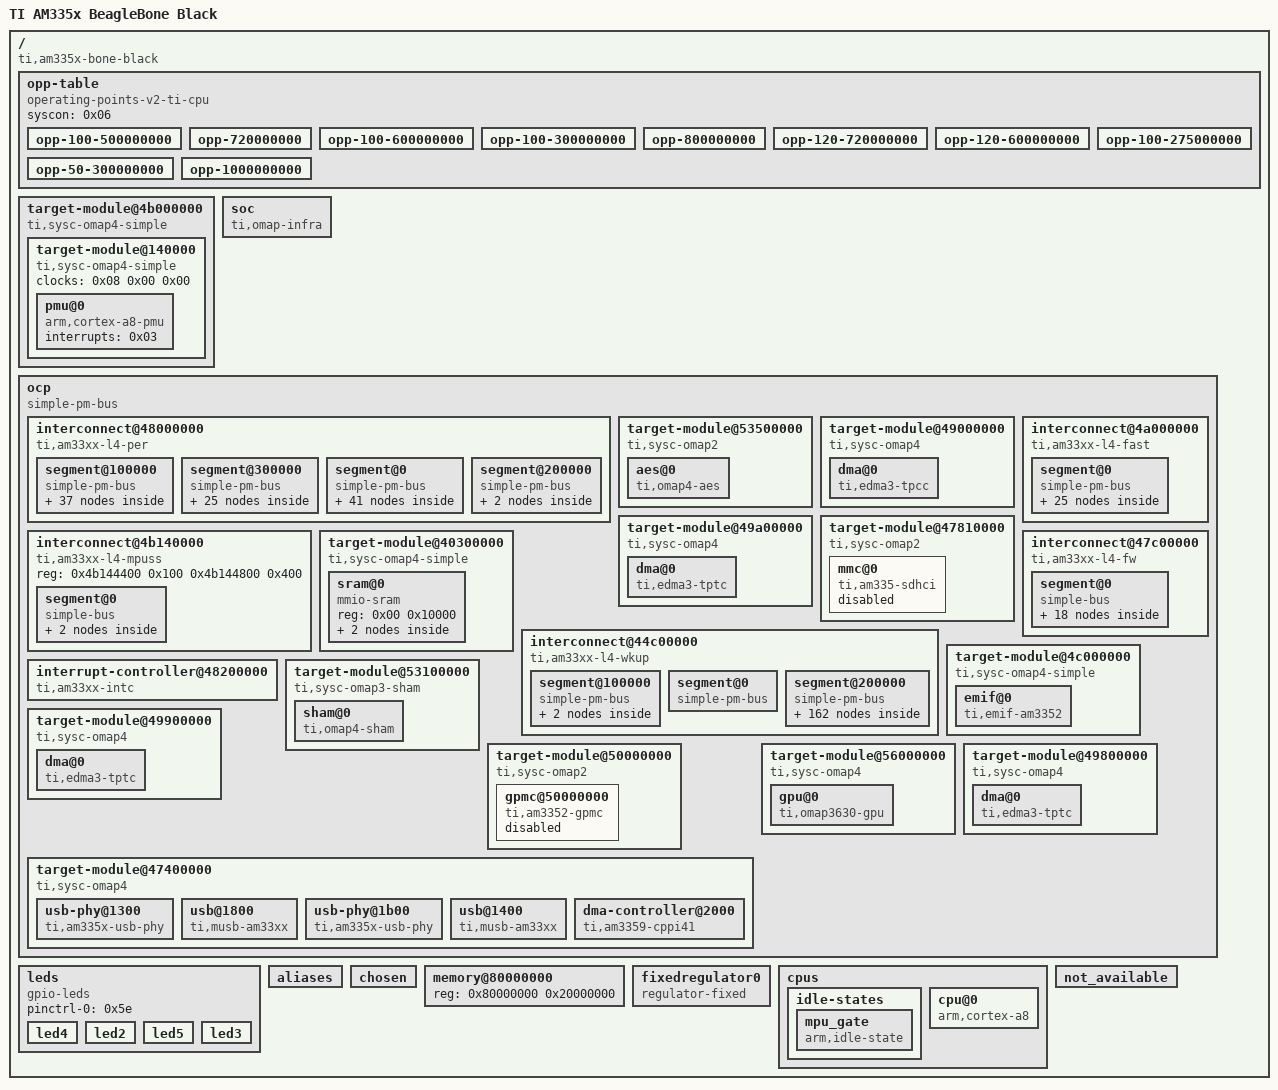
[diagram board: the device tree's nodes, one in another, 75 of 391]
/dts-v1/;

/ {
	compatible = "ti,am335x-bone-black\0ti,am335x-bone\0ti,am33xx";
	serial-number = "4016BBBK0E84";
	model = "TI AM335x BeagleBone Black";
	interrupt-parent = <0x01>;
	#address-cells = <0x01>;
	#size-cells = <0x01>;

	opp-table {
		compatible = "operating-points-v2-ti-cpu";
		phandle = <0x02>;
		syscon = <0x06>;

		opp-100-500000000 {
			opp-microvolt = <0x10c8e0 0x1072f0 0x111ed0>;
			opp-hz = <0x00 0x1dcd6500>;
			opp-supported-hw = <0x01 0xffff>;
		};

		opp-720000000 {
			opp-microvolt = <0x1339e0 0x12d770 0x139c50>;
			opp-hz = <0x00 0x2aea5400>;
			opp-supported-hw = <0x01 0xffff>;
		};

		opp-100-600000000 {
			opp-microvolt = <0x10c8e0 0x1072f0 0x111ed0>;
			opp-hz = <0x00 0x23c34600>;
			opp-supported-hw = <0x06 0x40>;
		};

		opp-100-300000000 {
			opp-microvolt = <0x10c8e0 0x1072f0 0x111ed0>;
			opp-hz = <0x00 0x11e1a300>;
			opp-suspend;
			opp-supported-hw = <0x06 0x20>;
		};

		opp-800000000 {
			opp-microvolt = <0x1339e0 0x12d770 0x139c50>;
			opp-hz = <0x00 0x2faf0800>;
			opp-supported-hw = <0x06 0x100>;
		};

		opp-120-720000000 {
			opp-microvolt = <0x124f80 0x11f1c0 0x12ad40>;
			opp-hz = <0x00 0x2aea5400>;
			opp-supported-hw = <0x06 0x80>;
		};

		opp-120-600000000 {
			opp-microvolt = <0x124f80 0x11f1c0 0x12ad40>;
			opp-hz = <0x00 0x23c34600>;
			opp-supported-hw = <0x01 0xffff>;
		};

		opp-100-275000000 {
			opp-microvolt = <0x10c8e0 0x1072f0 0x111ed0>;
			opp-hz = <0x00 0x10642ac0>;
			opp-suspend;
			opp-supported-hw = <0x01 0xff>;
		};

		opp-50-300000000 {
			opp-microvolt = <0xe7ef0 0xe34b8 0xec928>;
			opp-hz = <0x00 0x11e1a300>;
			opp-suspend;
			opp-supported-hw = <0x06 0x10>;
		};

		opp-1000000000 {
			opp-microvolt = <0x1437c8 0x13d044 0x149f4c>;
			opp-hz = <0x00 0x3b9aca00>;
			opp-supported-hw = <0x06 0x100>;
		};
	};

	target-module@4b000000 {
		compatible = "ti,sysc-omap4-simple\0ti,sysc";
		clocks = <0x07 0xb8 0x00>;
		clock-names = "fck";
		ti,no-idle;
		ranges = <0x00 0x4b000000 0x1000000>;
		#address-cells = <0x01>;
		#size-cells = <0x01>;

		target-module@140000 {
			compatible = "ti,sysc-omap4-simple\0ti,sysc";
			clocks = <0x08 0x00 0x00>;
			clock-names = "fck";
			ranges = <0x00 0x140000 0xec0000>;
			#address-cells = <0x01>;
			#size-cells = <0x01>;

			pmu@0 {
				compatible = "arm,cortex-a8-pmu";
				interrupts = <0x03>;
			};
		};
	};

	__symbols__ {
		dpll_per_m2_div4_wkupdm_ck = "/ocp/interconnect@44c00000/segment@200000/target-module@0/prcm@0/clocks/clock-dpll-per-m2-div4-wkupdm";
		cpsw_port1 = "/ocp/interconnect@4a000000/segment@0/target-module@100000/switch@0/ethernet-ports/port@1";
		sha0_fck = "/ocp/interconnect@44c00000/segment@200000/target-module@10000/scm@0/scm_conf@0/clocks/clock-sha0-fck";
		prm_mpu = "/ocp/interconnect@44c00000/segment@200000/target-module@0/prcm@0/prm@e00";
		dpll_core_m4_div2_ck = "/ocp/interconnect@44c00000/segment@200000/target-module@0/prcm@0/clocks/clock-dpll-core-m4-div2";
		cpsw_sleep = "/ocp/interconnect@44c00000/segment@200000/target-module@10000/scm@0/pinmux@800/cpsw-sleep-pins";
		ehrpwm2 = "/ocp/interconnect@48000000/segment@300000/target-module@4000/epwmss@0/pwm@200";
		gpio2 = "/ocp/interconnect@48000000/segment@100000/target-module@ac000/gpio@0";
		prm_gfx = "/ocp/interconnect@44c00000/segment@200000/target-module@0/prcm@0/prm@1100";
		intc = "/ocp/interrupt-controller@48200000";
		ecap2 = "/ocp/interconnect@48000000/segment@300000/target-module@4000/epwmss@0/pwm@100";
		dpll_ddr_m2_ck = "/ocp/interconnect@44c00000/segment@200000/target-module@0/prcm@0/clocks/clock-dpll-ddr-m2@4a0";
		tclkin_ck = "/ocp/interconnect@44c00000/segment@200000/target-module@0/prcm@0/clocks/clock-tclkin";
		edma_tptc0 = "/ocp/target-module@49800000/dma@0";
		l4_rtc_clkctrl = "/ocp/interconnect@44c00000/segment@200000/target-module@0/prcm@0/clock@800/clock@0";
		cape_eeprom3 = "/ocp/interconnect@48000000/segment@100000/target-module@9c000/i2c@0/eeprom@57";
		timer6 = "/ocp/interconnect@48000000/segment@0/target-module@48000/timer@0";
		l4_fast = "/ocp/interconnect@4a000000";
		bone_uart_4 = "/ocp/interconnect@48000000/segment@100000/target-module@a8000/serial@0";
		epwmss2 = "/ocp/interconnect@48000000/segment@300000/target-module@4000/epwmss@0";
		l3s_clkctrl = "/ocp/interconnect@44c00000/segment@200000/target-module@0/prcm@0/clock@0/clock@1c";
		dcan0_fck = "/ocp/interconnect@44c00000/segment@200000/target-module@10000/scm@0/scm_conf@0/clocks/clock-dcan0-fck";
		tps = "/ocp/interconnect@44c00000/segment@200000/target-module@b000/i2c@0/pmic@24";
		gfx_l3_clkctrl = "/ocp/interconnect@44c00000/segment@200000/target-module@0/prcm@0/clock@900/clock@0";
		mcasp0_fck = "/ocp/interconnect@44c00000/segment@200000/target-module@10000/scm@0/scm_conf@0/clocks/clock-mcasp0-fck";
		i2c1 = "/ocp/interconnect@48000000/segment@0/target-module@2a000/i2c@0";
		ldo3_reg = "/ocp/interconnect@44c00000/segment@200000/target-module@b000/i2c@0/pmic@24/regulators/regulator@5";
		dpll_core_m5_ck = "/ocp/interconnect@44c00000/segment@200000/target-module@0/prcm@0/clocks/clock-dpll-core-m5@484";
		mmc3 = "/ocp/target-module@47810000/mmc@0";
		l4_wkup = "/ocp/interconnect@44c00000";
		l4_fw = "/ocp/interconnect@47c00000";
		ehrpwm0 = "/ocp/interconnect@48000000/segment@300000/target-module@0/epwmss@0/pwm@200";
		aes_target = "/ocp/target-module@53500000";
		pru1 = "/ocp/interconnect@4a000000/segment@0/target-module@300000/pruss@0/pru@38000";
		gpio0 = "/ocp/interconnect@44c00000/segment@200000/target-module@7000/gpio@0";
		cpsw_default = "/ocp/interconnect@44c00000/segment@200000/target-module@10000/scm@0/pinmux@800/cpsw-default-pins";
		ecap0 = "/ocp/interconnect@48000000/segment@300000/target-module@0/epwmss@0/pwm@100";
		gpio0_target = "/ocp/interconnect@44c00000/segment@200000/target-module@7000";
		cape_eeprom1 = "/ocp/interconnect@48000000/segment@100000/target-module@9c000/i2c@0/eeprom@55";
		timer4 = "/ocp/interconnect@48000000/segment@0/target-module@44000/timer@0";
		spi0 = "/ocp/interconnect@48000000/segment@0/target-module@30000/spi@0";
		prm_device = "/ocp/interconnect@44c00000/segment@200000/target-module@0/prcm@0/prm@f00";
		davinci_mdio_sleep = "/ocp/interconnect@44c00000/segment@200000/target-module@10000/scm@0/pinmux@800/davinci-mdio-sleep-pins";
		gfx_fclk_clksel_ck = "/ocp/interconnect@44c00000/segment@200000/target-module@0/prcm@0/clocks/clock@52c/clock-gfx-fclk-clksel@1";
		prm_cefuse = "/ocp/interconnect@44c00000/segment@200000/target-module@0/prcm@0/prm@1200";
		dpll_ddr_m2_div2_ck = "/ocp/interconnect@44c00000/segment@200000/target-module@0/prcm@0/clocks/clock-dpll-ddr-m2-div2";
		pruss = "/ocp/interconnect@4a000000/segment@0/target-module@300000/pruss@0";
		epwmss0 = "/ocp/interconnect@48000000/segment@300000/target-module@0/epwmss@0";
		dpll_disp_ck = "/ocp/interconnect@44c00000/segment@200000/target-module@0/prcm@0/clocks/clock@498";
		wkup_m3_ipc = "/ocp/interconnect@44c00000/segment@200000/target-module@10000/scm@0/wkup_m3_ipc@1324";
		l4ls_clkctrl = "/ocp/interconnect@44c00000/segment@200000/target-module@0/prcm@0/clock@0/clock@38";
		timer1_fck = "/ocp/interconnect@44c00000/segment@200000/target-module@0/prcm@0/clocks/clock-timer1-fck@528";
		mmc1 = "/ocp/interconnect@48000000/segment@0/target-module@60000/mmc@0";
		scm = "/ocp/interconnect@44c00000/segment@200000/target-module@10000/scm@0";
		usb1 = "/ocp/target-module@47400000/usb@1800";
		sham_target = "/ocp/target-module@53100000";
		sysclkout_pre_ck = "/ocp/interconnect@44c00000/segment@200000/target-module@0/prcm@0/clocks/clock@700/clock-sysclkout-pre@0";
		cpsw_emac1 = "/ocp/interconnect@4a000000/segment@0/target-module@100000/ethernet@0/slave@300";
		lcd_gclk = "/ocp/interconnect@44c00000/segment@200000/target-module@0/prcm@0/clocks/clock-lcd-gclk@534";
		am33xx_pinmux = "/ocp/interconnect@44c00000/segment@200000/target-module@10000/scm@0/pinmux@800";
		clk_24mhz_clkctrl = "/ocp/interconnect@44c00000/segment@200000/target-module@0/prcm@0/clock@0/clock@14c";
		bone_adc = "/ocp/interconnect@44c00000/segment@200000/target-module@d000/tscadc@0";
		timer5_fck = "/ocp/interconnect@44c00000/segment@200000/target-module@0/prcm@0/clocks/clock-timer5-fck@518";
		user_leds_s0 = "/ocp/interconnect@44c00000/segment@200000/target-module@10000/scm@0/pinmux@800/user-leds-s0-pins";
		l4ls_gclk = "/ocp/interconnect@44c00000/segment@200000/target-module@0/prcm@0/clocks/clock-l4ls-gclk";
		timer2 = "/ocp/interconnect@48000000/segment@0/target-module@40000/timer@0";
		mmc1_pins = "/ocp/interconnect@44c00000/segment@200000/target-module@10000/scm@0/pinmux@800/mmc1-pins";
		mac_sw = "/ocp/interconnect@4a000000/segment@0/target-module@100000/switch@0";
		mbox_wkupm3 = "/ocp/interconnect@48000000/segment@0/target-module@c8000/mailbox@0/mbox-wkup-m3";
		dpll_disp_m2_ck = "/ocp/interconnect@44c00000/segment@200000/target-module@0/prcm@0/clocks/clock-dpll-disp-m2@4a4";
		pm_sram_code = "/ocp/target-module@40300000/sram@0/pm-code-sram@0";
		edma = "/ocp/target-module@49000000/dma@0";
		virt_25000000_ck = "/ocp/interconnect@44c00000/segment@200000/target-module@0/prcm@0/clocks/clock-virt-25000000";
		lcdc_clkctrl = "/ocp/interconnect@44c00000/segment@200000/target-module@0/prcm@0/clock@0/clock@18";
		l4_rtc_cm = "/ocp/interconnect@44c00000/segment@200000/target-module@0/prcm@0/clock@800";
		adc_tsc_fck = "/ocp/interconnect@44c00000/segment@200000/target-module@10000/scm@0/scm_conf@0/clocks/clock-adc-tsc-fck";
		mpu_gate = "/cpus/idle-states/mpu_gate";
		uart4 = "/ocp/interconnect@48000000/segment@100000/target-module@a8000/serial@0";
		ehrpwm1_tbclk = "/ocp/interconnect@44c00000/segment@200000/target-module@10000/scm@0/scm_conf@0/clocks/clock@664/clock-ehrpwm1-tbclk@1";
		cppi41dma = "/ocp/target-module@47400000/dma-controller@2000";
		dpll_per_ck = "/ocp/interconnect@44c00000/segment@200000/target-module@0/prcm@0/clocks/clock@48c";
		dpll_per_m2_div4_ck = "/ocp/interconnect@44c00000/segment@200000/target-module@0/prcm@0/clocks/clock-dpll-per-m2-div4";
		dcdc1_reg = "/ocp/interconnect@44c00000/segment@200000/target-module@b000/i2c@0/pmic@24/regulators/regulator@0";
		mcasp0 = "/ocp/interconnect@48000000/segment@0/target-module@38000/mcasp@0";
		dcan1_fck = "/ocp/interconnect@44c00000/segment@200000/target-module@10000/scm@0/scm_conf@0/clocks/clock-dcan1-fck";
		eqep1 = "/ocp/interconnect@48000000/segment@300000/target-module@2000/epwmss@0/counter@180";
		i2c2_pins = "/ocp/interconnect@44c00000/segment@200000/target-module@10000/scm@0/pinmux@800/i2c2-pins";
		mcasp1_fck = "/ocp/interconnect@44c00000/segment@200000/target-module@10000/scm@0/scm_conf@0/clocks/clock-mcasp1-fck";
		ldo4_reg = "/ocp/interconnect@44c00000/segment@200000/target-module@b000/i2c@0/pmic@24/regulators/regulator@6";
		lcdc = "/ocp/interconnect@48000000/segment@300000/target-module@e000/lcdc@0";
		cpu = "/cpus/cpu@0";
		emmc_pins = "/ocp/interconnect@44c00000/segment@200000/target-module@10000/scm@0/pinmux@800/emmc-pins";
		edma_xbar = "/ocp/interconnect@44c00000/segment@200000/target-module@10000/scm@0/dma-router@f90";
		ocmcram = "/ocp/target-module@40300000/sram@0";
		pm_sram_data = "/ocp/target-module@40300000/sram@0/pm-data-sram@1000";
		l4_mpuss = "/ocp/interconnect@4b140000";
		ocp = "/ocp";
		am335x_adc = "/ocp/interconnect@44c00000/segment@200000/target-module@d000/tscadc@0/adc";
		pruss_tm = "/ocp/interconnect@4a000000/segment@0/target-module@300000";
		mpu_clkctrl = "/ocp/interconnect@44c00000/segment@200000/target-module@0/prcm@0/clock@600/clock@0";
		l3_aon_clkctrl = "/ocp/interconnect@44c00000/segment@200000/target-module@0/prcm@0/clock@400/clock@14";
		uart2 = "/ocp/interconnect@48000000/segment@0/target-module@24000/serial@0";
		prm_per = "/ocp/interconnect@44c00000/segment@200000/target-module@0/prcm@0/prm@c00";
		elm = "/ocp/interconnect@48000000/segment@0/target-module@80000/elm@0";
		scm_clocks = "/ocp/interconnect@44c00000/segment@200000/target-module@10000/scm@0/scm_conf@0/clocks";
		dpll_mpu_ck = "/ocp/interconnect@44c00000/segment@200000/target-module@0/prcm@0/clocks/clock@488";
		l4_per = "/ocp/interconnect@48000000";
		dpll_core_m4_ck = "/ocp/interconnect@44c00000/segment@200000/target-module@0/prcm@0/clocks/clock-dpll-core-m4@480";
		cape3_data = "/ocp/interconnect@48000000/segment@100000/target-module@9c000/i2c@0/eeprom@57/nvmem-layout/cape_data@0";
		cpsw_port2 = "/ocp/interconnect@4a000000/segment@0/target-module@100000/switch@0/ethernet-ports/port@2";
		l3_clkctrl = "/ocp/interconnect@44c00000/segment@200000/target-module@0/prcm@0/clock@0/clock@24";
		timer2_fck = "/ocp/interconnect@44c00000/segment@200000/target-module@0/prcm@0/clocks/clock-timer2-fck@508";
		wkup_cm = "/ocp/interconnect@44c00000/segment@200000/target-module@0/prcm@0/clock@400";
		davinci_mdio_default = "/ocp/interconnect@44c00000/segment@200000/target-module@10000/scm@0/pinmux@800/davinci-mdio-default-pins";
		bone_pinmux = "/ocp/interconnect@44c00000/segment@200000/target-module@10000/scm@0/pinmux@800";
		prcm_clockdomains = "/ocp/interconnect@44c00000/segment@200000/target-module@0/prcm@0/clockdomains";
		gpio3 = "/ocp/interconnect@48000000/segment@100000/target-module@ae000/gpio@0";
		sysclk_div_ck = "/ocp/interconnect@44c00000/segment@200000/target-module@0/prcm@0/clocks/clock-sysclk-div";
		l3s_gclk = "/ocp/interconnect@44c00000/segment@200000/target-module@0/prcm@0/clocks/clock-l3s-gclk";
		rng = "/ocp/interconnect@48000000/segment@300000/target-module@10000/rng@0";
		timer6_fck = "/ocp/interconnect@44c00000/segment@200000/target-module@0/prcm@0/clocks/clock-timer6-fck@51c";
		dpll_mpu_m2_ck = "/ocp/interconnect@44c00000/segment@200000/target-module@0/prcm@0/clocks/clock-dpll-mpu-m2@4a8";
		dcan0 = "/ocp/interconnect@48000000/segment@100000/target-module@cc000/can@0";
		scm_clockdomains = "/ocp/interconnect@44c00000/segment@200000/target-module@10000/scm@0/clockdomains";
		uart0 = "/ocp/interconnect@44c00000/segment@200000/target-module@9000/serial@0";
		edma_tptc1 = "/ocp/target-module@49900000/dma@0";
		smartreflex0_fck = "/ocp/interconnect@44c00000/segment@200000/target-module@10000/scm@0/scm_conf@0/clocks/clock-smartreflex0-fck";
		timer7 = "/ocp/interconnect@48000000/segment@0/target-module@4a000/timer@0";
		davinci_mdio_sw = "/ocp/interconnect@4a000000/segment@0/target-module@100000/switch@0/mdio@1000";
		prcm = "/ocp/interconnect@44c00000/segment@200000/target-module@0/prcm@0";
		usbotg_fck = "/ocp/interconnect@44c00000/segment@200000/target-module@0/prcm@0/clocks/clock-usbotg-fck-8@47c";
		pruss_mem = "/ocp/interconnect@4a000000/segment@0/target-module@300000/pruss@0/memories@0";
		gfx_fck_div_ck = "/ocp/interconnect@44c00000/segment@200000/target-module@0/prcm@0/clocks/clock@52c/clock-gfx-fck-div@0";
		cpsw_125mhz_clkctrl = "/ocp/interconnect@44c00000/segment@200000/target-module@0/prcm@0/clock@0/clock@0";
		l4_cefuse_cm = "/ocp/interconnect@44c00000/segment@200000/target-module@0/prcm@0/clock@a00";
		baseboard_data = "/ocp/interconnect@44c00000/segment@200000/target-module@b000/i2c@0/eeprom@50/nvmem-layout/baseboard_data@0";
		l4fw_gclk = "/ocp/interconnect@44c00000/segment@200000/target-module@0/prcm@0/clocks/clock-l4fw-gclk";
		l3_gclk = "/ocp/interconnect@44c00000/segment@200000/target-module@0/prcm@0/clocks/clock-l3-gclk";
		i2c2 = "/ocp/interconnect@48000000/segment@100000/target-module@9c000/i2c@0";
		davinci_mdio = "/ocp/interconnect@4a000000/segment@0/target-module@100000/ethernet@0/mdio@1000";
		clk_24mhz = "/ocp/interconnect@44c00000/segment@200000/target-module@0/prcm@0/clocks/clock-clk-24mhz";
		ehrpwm1 = "/ocp/interconnect@48000000/segment@300000/target-module@2000/epwmss@0/pwm@200";
		wdt1_fck = "/ocp/interconnect@44c00000/segment@200000/target-module@0/prcm@0/clocks/clock-wdt1-fck@538";
		gpio1 = "/ocp/interconnect@48000000/segment@0/target-module@4c000/gpio@0";
		dpll_per_m2_ck = "/ocp/interconnect@44c00000/segment@200000/target-module@0/prcm@0/clocks/clock-dpll-per-m2@4ac";
		ldo1_reg = "/ocp/interconnect@44c00000/segment@200000/target-module@b000/i2c@0/pmic@24/regulators/regulator@3";
		dcdc2_reg = "/ocp/interconnect@44c00000/segment@200000/target-module@b000/i2c@0/pmic@24/regulators/regulator@1";
		ecap1 = "/ocp/interconnect@48000000/segment@300000/target-module@2000/epwmss@0/pwm@100";
		cape2_data = "/ocp/interconnect@48000000/segment@100000/target-module@9c000/i2c@0/eeprom@56/nvmem-layout/cape_data@0";
		virt_26000000_ck = "/ocp/interconnect@44c00000/segment@200000/target-module@0/prcm@0/clocks/clock-virt-26000000";
		cape_eeprom2 = "/ocp/interconnect@48000000/segment@100000/target-module@9c000/i2c@0/eeprom@56";
		timer5 = "/ocp/interconnect@48000000/segment@0/target-module@46000/timer@0";
		spi1 = "/ocp/interconnect@48000000/segment@100000/target-module@a0000/spi@0";
		usb = "/ocp/target-module@47400000";
		epwmss1 = "/ocp/interconnect@48000000/segment@300000/target-module@2000/epwmss@0";
		pruss_ocp_clkctrl = "/ocp/interconnect@44c00000/segment@200000/target-module@0/prcm@0/clock@0/clock@e8";
		pruss_iepclk_mux = "/ocp/interconnect@4a000000/segment@0/target-module@300000/pruss@0/cfg@26000/clocks/iepclk-mux@30";
		pruss_mii_rt = "/ocp/interconnect@4a000000/segment@0/target-module@300000/pruss@0/mii-rt@32000";
		prm_rtc = "/ocp/interconnect@44c00000/segment@200000/target-module@0/prcm@0/prm@1000";
		sys_clkin_ck = "/ocp/interconnect@44c00000/segment@200000/target-module@10000/scm@0/scm_conf@0/clocks/clock-sys-clkin-22@40";
		i2c0 = "/ocp/interconnect@44c00000/segment@200000/target-module@b000/i2c@0";
		timer2_target = "/ocp/interconnect@48000000/segment@0/target-module@40000";
		mmc2 = "/ocp/interconnect@48000000/segment@100000/target-module@d8000/mmc@0";
		i2c0_pins = "/ocp/interconnect@44c00000/segment@200000/target-module@10000/scm@0/pinmux@800/i2c0-pins";
		ehrpwm2_tbclk = "/ocp/interconnect@44c00000/segment@200000/target-module@10000/scm@0/scm_conf@0/clocks/clock@664/clock-ehrpwm2-tbclk@2";
		bborg_comms_rs485_pins = "/ocp/interconnect@44c00000/segment@200000/target-module@10000/scm@0/pinmux@800/pinmux_comms_rs485_pins";
		gpmc = "/ocp/target-module@50000000/gpmc@50000000";
		aes0_fck = "/ocp/interconnect@44c00000/segment@200000/target-module@10000/scm@0/scm_conf@0/clocks/clock-aes0-fck";
		pru0 = "/ocp/interconnect@4a000000/segment@0/target-module@300000/pruss@0/pru@34000";
		dpll_core_ck = "/ocp/interconnect@44c00000/segment@200000/target-module@0/prcm@0/clocks/clock@490";
		dpll_ddr_ck = "/ocp/interconnect@44c00000/segment@200000/target-module@0/prcm@0/clocks/clock@494";
		wdt2 = "/ocp/interconnect@44c00000/segment@200000/target-module@35000/wdt@0";
		cpu0_opp_table = "/opp-table";
		gpio3_target = "/ocp/interconnect@48000000/segment@100000/target-module@ae000";
		cpsw_125mhz_gclk = "/ocp/interconnect@44c00000/segment@200000/target-module@0/prcm@0/clocks/clock-cpsw-125mhz-gclk";
		pruss_ocp_gclk = "/ocp/interconnect@44c00000/segment@200000/target-module@0/prcm@0/clocks/clock-pruss-ocp-gclk@530";
		cape_eeprom0 = "/ocp/interconnect@48000000/segment@100000/target-module@9c000/i2c@0/eeprom@54";
		timer3 = "/ocp/interconnect@48000000/segment@0/target-module@42000/timer@0";
		usb0_phy = "/ocp/target-module@47400000/usb-phy@1300";
		rng_fck = "/ocp/interconnect@44c00000/segment@200000/target-module@10000/scm@0/scm_conf@0/clocks/clock-rng-fck";
		uart0_pins = "/ocp/interconnect@44c00000/segment@200000/target-module@10000/scm@0/pinmux@800/uart0-pins";
		usb_ctrl_mod = "/ocp/interconnect@44c00000/segment@200000/target-module@10000/scm@0/control@620";
		prm_wkup = "/ocp/interconnect@44c00000/segment@200000/target-module@0/prcm@0/prm@d00";
		timer3_fck = "/ocp/interconnect@44c00000/segment@200000/target-module@0/prcm@0/clocks/clock-timer3-fck@50c";
		per_cm = "/ocp/interconnect@44c00000/segment@200000/target-module@0/prcm@0/clock@0";
		scm_conf = "/ocp/interconnect@44c00000/segment@200000/target-module@10000/scm@0/scm_conf@0";
		virt_19200000_ck = "/ocp/interconnect@44c00000/segment@200000/target-module@0/prcm@0/clocks/clock-virt-19200000";
		cape1_data = "/ocp/interconnect@48000000/segment@100000/target-module@9c000/i2c@0/eeprom@55/nvmem-layout/cape_data@0";
		prcm_clocks = "/ocp/interconnect@44c00000/segment@200000/target-module@0/prcm@0/clocks";
		timer7_fck = "/ocp/interconnect@44c00000/segment@200000/target-module@0/prcm@0/clocks/clock-timer7-fck@504";
		wkup_m3 = "/ocp/interconnect@44c00000/segment@100000/target-module@0/cpu@0";
		ethphy0 = "/ocp/interconnect@4a000000/segment@0/target-module@100000/switch@0/mdio@1000/ethernet-phy@0";
		usb0 = "/ocp/target-module@47400000/usb@1400";
		uart5 = "/ocp/interconnect@48000000/segment@100000/target-module@aa000/serial@0";
		dpll_core_m6_ck = "/ocp/interconnect@44c00000/segment@200000/target-module@0/prcm@0/clocks/clock-dpll-core-m6@4d8";
		cpsw_emac0 = "/ocp/interconnect@4a000000/segment@0/target-module@100000/ethernet@0/slave@200";
		smartreflex1_fck = "/ocp/interconnect@44c00000/segment@200000/target-module@10000/scm@0/scm_conf@0/clocks/clock-smartreflex1-fck";
		mac = "/ocp/interconnect@4a000000/segment@0/target-module@100000/ethernet@0";
		clk_rc32k_ck = "/ocp/interconnect@44c00000/segment@200000/target-module@0/prcm@0/clocks/clock-clk-rc32k";
		mmc_clk = "/ocp/interconnect@44c00000/segment@200000/target-module@0/prcm@0/clocks/clock-mmc";
		tscadc = "/ocp/interconnect@44c00000/segment@200000/target-module@d000/tscadc@0";
		bone_can_1 = "/ocp/interconnect@48000000/segment@100000/target-module@d0000/can@0";
		l4_rtc_gclk = "/ocp/interconnect@44c00000/segment@200000/target-module@0/prcm@0/clocks/clock-l4-rtc-gclk";
		clkdiv32k_ck = "/ocp/interconnect@44c00000/segment@200000/target-module@0/prcm@0/clocks/clock-clkdiv32k";
		mmu_fck = "/ocp/interconnect@44c00000/segment@200000/target-module@0/prcm@0/clocks/clock-mmu-fck-1@914";
		ieee5000_fck = "/ocp/interconnect@44c00000/segment@200000/target-module@0/prcm@0/clocks/clock-ieee5000-fck-1@e4";
		mcasp1 = "/ocp/interconnect@48000000/segment@0/target-module@3c000/mcasp@0";
		eqep2 = "/ocp/interconnect@48000000/segment@300000/target-module@4000/epwmss@0/counter@180";
		sham = "/ocp/target-module@53100000/sham@0";
		timer1 = "/ocp/interconnect@44c00000/segment@200000/target-module@31000/timer@0";
		timer1_target = "/ocp/interconnect@44c00000/segment@200000/target-module@31000";
		pruss_cfg = "/ocp/interconnect@4a000000/segment@0/target-module@300000/pruss@0/cfg@26000";
		ldo2_reg = "/ocp/interconnect@44c00000/segment@200000/target-module@b000/i2c@0/pmic@24/regulators/regulator@4";
		l4hs_gclk = "/ocp/interconnect@44c00000/segment@200000/target-module@0/prcm@0/clocks/clock-l4hs-gclk";
		dcdc3_reg = "/ocp/interconnect@44c00000/segment@200000/target-module@b000/i2c@0/pmic@24/regulators/regulator@2";
		mpu_cm = "/ocp/interconnect@44c00000/segment@200000/target-module@0/prcm@0/clock@600";
		l4_cefuse_clkctrl = "/ocp/interconnect@44c00000/segment@200000/target-module@0/prcm@0/clock@a00/clock@0";
		uart3 = "/ocp/interconnect@48000000/segment@100000/target-module@a6000/serial@0";
		baseboard_eeprom = "/ocp/interconnect@44c00000/segment@200000/target-module@b000/i2c@0/eeprom@50";
		cpsw_cpts_rft_clk = "/ocp/interconnect@44c00000/segment@200000/target-module@0/prcm@0/clocks/clock-cpsw-cpts-rft@520";
		clk_32768_ck = "/ocp/interconnect@44c00000/segment@200000/target-module@0/prcm@0/clocks/clock-clk-32768";
		phy_gmii_sel = "/ocp/interconnect@44c00000/segment@200000/target-module@10000/scm@0/scm_conf@0/phy-gmii-sel";
		l4_wkup_clkctrl = "/ocp/interconnect@44c00000/segment@200000/target-module@0/prcm@0/clock@400/clock@0";
		eqep0 = "/ocp/interconnect@48000000/segment@300000/target-module@0/epwmss@0/counter@180";
		cape0_data = "/ocp/interconnect@48000000/segment@100000/target-module@9c000/i2c@0/eeprom@54/nvmem-layout/cape_data@0";
		not_available = "/not_available";
		clkout2_div_ck = "/ocp/interconnect@44c00000/segment@200000/target-module@0/prcm@0/clocks/clock@700/clock-clkout2-div@3";
		gpio0_dbclk_mux_ck = "/ocp/interconnect@44c00000/segment@200000/target-module@0/prcm@0/clocks/clock-gpio0-dbclk-mux@53c";
		emif = "/ocp/target-module@4c000000/emif@0";
		gfx_l3_cm = "/ocp/interconnect@44c00000/segment@200000/target-module@0/prcm@0/clock@900";
		aes = "/ocp/target-module@53500000/aes@0";
		clkout2_ck = "/ocp/interconnect@44c00000/segment@200000/target-module@0/prcm@0/clocks/clock@700/clock-clkout2@7";
		mailbox = "/ocp/interconnect@48000000/segment@0/target-module@c8000/mailbox@0";
		hwspinlock = "/ocp/interconnect@48000000/segment@0/target-module@ca000/spinlock@0";
		pruss_mdio = "/ocp/interconnect@4a000000/segment@0/target-module@300000/pruss@0/mdio@32400";
		dcan1 = "/ocp/interconnect@48000000/segment@100000/target-module@d0000/can@0";
		uart1 = "/ocp/interconnect@48000000/segment@0/target-module@22000/serial@0";
		rtc = "/ocp/interconnect@44c00000/segment@200000/target-module@3e000/rtc@0";
		edma_tptc2 = "/ocp/target-module@49a00000/dma@0";
		ehrpwm0_tbclk = "/ocp/interconnect@44c00000/segment@200000/target-module@10000/scm@0/scm_conf@0/clocks/clock@664/clock-ehrpwm0-tbclk@0";
		usb1_phy = "/ocp/target-module@47400000/usb-phy@1b00";
		l4hs_clkctrl = "/ocp/interconnect@44c00000/segment@200000/target-module@0/prcm@0/clock@0/clock@120";
		l4_wkup_aon_clkctrl = "/ocp/interconnect@44c00000/segment@200000/target-module@0/prcm@0/clock@400/clock@b0";
		vmmcsd_fixed = "/fixedregulator0";
		timer4_fck = "/ocp/interconnect@44c00000/segment@200000/target-module@0/prcm@0/clocks/clock-timer4-fck@510";
		pruss_intc = "/ocp/interconnect@4a000000/segment@0/target-module@300000/pruss@0/interrupt-controller@20000";
		virt_24000000_ck = "/ocp/interconnect@44c00000/segment@200000/target-module@0/prcm@0/clocks/clock-virt-24000000";
		dpll_core_x2_ck = "/ocp/interconnect@44c00000/segment@200000/target-module@0/prcm@0/clocks/clock-dpll-core-x2";
		bborg_comms_can_pins = "/ocp/interconnect@44c00000/segment@200000/target-module@10000/scm@0/pinmux@800/pinmux_comms_can_pins";
	};

	soc {
		compatible = "ti,omap-infra";
	};

	ocp {
		power-domains = <0x09>;
		compatible = "simple-pm-bus";
		clocks = <0x07 0xbc 0x00>;
		clock-names = "fck";
		ranges;
		#address-cells = <0x01>;
		#size-cells = <0x01>;
		phandle = <0x60>;

		interconnect@48000000 {
			power-domains = <0x09>;
			compatible = "ti,am33xx-l4-per\0simple-pm-bus";
			clocks = <0x34 0x28 0x00>;
			reg-names = "ap\0la\0ia0\0ia1\0ia2\0ia3";
			clock-names = "fck";
			ranges = <0x00 0x48000000 0x100000 0x100000 0x48100000 0x100000 0x200000 0x48200000 0x100000 0x300000 0x48300000 0x100000 0x46000000 0x46000000 0x400000 0x46400000 0x46400000 0x400000>;
			#address-cells = <0x01>;
			#size-cells = <0x01>;
			phandle = <0xa3>;
			reg = <0x48000000 0x800 0x48000800 0x800 0x48001000 0x400 0x48001400 0x400 0x48001800 0x400 0x48001c00 0x400>;

			segment@100000 {
				compatible = "simple-pm-bus";
				ranges = <0x8c000 0x18c000 0x1000 0x8d000 0x18d000 0x1000 0x8e000 0x18e000 0x1000 0x8f000 0x18f000 0x1000 0x9c000 0x19c000 0x1000 0x9d000 0x19d000 0x1000 0xa6000 0x1a6000 0x1000 0xa7000 0x1a7000 0x1000 0xa8000 0x1a8000 0x1000 0xa9000 0x1a9000 0x1000 0xaa000 0x1aa000 0x1000 0xab000 0x1ab000 0x1000 0xac000 0x1ac000 0x1000 0xad000 0x1ad000 0x1000 0xae000 0x1ae000 0x1000 0xaf000 0x1af000 0x1000 0xb0000 0x1b0000 0x10000 0xc0000 0x1c0000 0x1000 0xcc000 0x1cc000 0x2000 0xce000 0x1ce000 0x2000 0xd0000 0x1d0000 0x2000 0xd2000 0x1d2000 0x2000 0xd8000 0x1d8000 0x1000 0xd9000 0x1d9000 0x1000 0xa0000 0x1a0000 0x1000 0xa1000 0x1a1000 0x1000 0xa2000 0x1a2000 0x1000 0xa3000 0x1a3000 0x1000 0xa4000 0x1a4000 0x1000 0xa5000 0x1a5000 0x1000>;
				#address-cells = <0x01>;
				#size-cells = <0x01>;

				target-module@a6000 {
					compatible = "ti,sysc-omap2\0ti,sysc";
					clocks = <0x34 0x3c 0x00>;
					reg-names = "rev\0sysc\0syss";
					clock-names = "fck";
					ti,sysc-mask = <0x07>;
					ranges = <0x00 0xa6000 0x1000>;
					#address-cells = <0x01>;
					#size-cells = <0x01>;
					ti,sysc-sidle = <0x00 0x01 0x02 0x03>;
					reg = <0xa6050 0x04 0xa6054 0x04 0xa6058 0x04>;

					serial@0 {
						compatible = "ti,am3352-uart\0ti,omap3-uart";
						status = "disabled";
						interrupts = <0x2c>;
						phandle = <0xbe>;
						reg = <0x00 0x1000>;
						clock-frequency = <0x2dc6c00>;
					};
				};

				target-module@a0000 {
					compatible = "ti,sysc-omap2\0ti,sysc";
					clocks = <0x34 0x18 0x00>;
					reg-names = "rev\0sysc\0syss";
					ti,syss-mask = <0x01>;
					clock-names = "fck";
					ti,sysc-mask = <0x303>;
					ranges = <0x00 0xa0000 0x1000>;
					#address-cells = <0x01>;
					#size-cells = <0x01>;
					ti,sysc-sidle = <0x00 0x01 0x02>;
					reg = <0xa0000 0x04 0xa0110 0x04 0xa0114 0x04>;

					spi@0 {
						compatible = "ti,omap4-mcspi";
						status = "disabled";
						#address-cells = <0x01>;
						interrupts = <0x7d>;
						#size-cells = <0x00>;
						dma-names = "tx0\0rx0\0tx1\0rx1";
						phandle = <0xbd>;
						reg = <0x00 0x400>;
						dmas = <0x24 0x2a 0x00 0x24 0x2b 0x00 0x24 0x2c 0x00 0x24 0x2d 0x00>;
						ti,spi-num-cs = <0x02>;
					};
				};

				target-module@d8000 {
					compatible = "ti,sysc-omap2\0ti,sysc";
					clocks = <0x34 0xbc 0x00>;
					reg-names = "rev\0sysc\0syss";
					ti,syss-mask = <0x01>;
					clock-names = "fck";
					ti,sysc-mask = <0x307>;
					ranges = <0x00 0xd8000 0x1000>;
					#address-cells = <0x01>;
					#size-cells = <0x01>;
					ti,sysc-sidle = <0x00 0x01 0x02>;
					reg = <0xd82fc 0x04 0xd8110 0x04 0xd8114 0x04>;

					mmc@0 {
						compatible = "ti,am335-sdhci";
						status = "disabled";
						interrupts = <0x1c>;
						ti,needs-special-reset;
						dma-names = "tx\0rx";
						phandle = <0xc6>;
						reg = <0x00 0x1000>;
						dmas = <0x24 0x02 0x00 0x24 0x03 0x00>;
					};
				};

				target-module@ae000 {
					compatible = "ti,sysc-omap2\0ti,sysc";
					clocks = <0x34 0x7c 0x00 0x34 0x7c 0x12>;
					reg-names = "rev\0sysc\0syss";
					ti,syss-mask = <0x01>;
					clock-names = "fck\0dbclk";
					ti,sysc-mask = <0x07>;
					ranges = <0x00 0xae000 0x1000>;
					#address-cells = <0x01>;
					#size-cells = <0x01>;
					ti,sysc-sidle = <0x00 0x01 0x02 0x03>;
					phandle = <0xc2>;
					reg = <0xae000 0x04 0xae010 0x04 0xae114 0x04>;

					gpio@0 {
						compatible = "ti,omap4-gpio";
						gpio-line-names = "[mii col]\0[mii crs]\0[mii rx err]\0[mii tx en]\0[mii rx dv]\0[i2c0 sda]\0[i2c0 scl]\0[jtag emu0]\0[jtag emu1]\0[mii tx clk]\0[mii rx clk]\0NC\0NC\0[usb vbus en]\0P9_31 [spi1_sclk]\0P9_29 [spi1_d0]\0P9_30 [spi1_d1]\0P9_28 [spi1_cs0]\0P9_42B [ecappwm0]\0P9_27\0P9_41A\0P9_25\0NC\0NC\0NC\0NC\0NC\0NC\0NC\0NC\0NC\0NC";
						gpio-controller;
						gpio-ranges = <0x23 0x00 0x42 0x05 0x23 0x05 0x62 0x02 0x23 0x07 0x4b 0x02 0x23 0x0d 0x8d 0x01 0x23 0x0e 0x64 0x08>;
						#interrupt-cells = <0x02>;
						interrupts = <0x3e>;
						phandle = <0xc3>;
						reg = <0x00 0x1000>;
						#gpio-cells = <0x02>;
						interrupt-controller;
					};
				};

				target-module@8c000 {
					compatible = "ti,sysc";
					ranges = <0x00 0x8c000 0x1000>;
					status = "disabled";
					#address-cells = <0x01>;
					#size-cells = <0x01>;
				};

				target-module@b0000 {
					compatible = "ti,sysc";
					ranges = <0x00 0xb0000 0x10000>;
					status = "disabled";
					#address-cells = <0x01>;
					#size-cells = <0x01>;
				};

				target-module@a8000 {
					compatible = "ti,sysc-omap2\0ti,sysc";
					clocks = <0x34 0x40 0x00>;
					reg-names = "rev\0sysc\0syss";
					clock-names = "fck";
					ti,sysc-mask = <0x07>;
					ranges = <0x00 0xa8000 0x1000>;
					#address-cells = <0x01>;
					#size-cells = <0x01>;
					ti,sysc-sidle = <0x00 0x01 0x02 0x03>;
					reg = <0xa8050 0x04 0xa8054 0x04 0xa8058 0x04>;

					serial@0 {
						compatible = "ti,am3352-uart\0ti,omap3-uart";
						symlink = "bone/uart/4";
						status = "disabled";
						interrupts = <0x2d>;
						phandle = <0xbf>;
						reg = <0x00 0x1000>;
						clock-frequency = <0x2dc6c00>;
						pinctrl-0 = <0x3b>;
						pinctrl-names = "default";
					};
				};

				target-module@a2000 {
					compatible = "ti,sysc";
					ranges = <0x00 0xa2000 0x1000>;
					status = "disabled";
					#address-cells = <0x01>;
					#size-cells = <0x01>;
				};

				target-module@cc000 {
					compatible = "ti,sysc-omap4\0ti,sysc";
					clocks = <0x34 0x88 0x00 0x3c>;
					reg-names = "rev";
					clock-names = "fck\0osc";
					ranges = <0x00 0xcc000 0x2000>;
					#address-cells = <0x01>;
					#size-cells = <0x01>;
					reg = <0xcc020 0x04>;

					can@0 {
						compatible = "ti,am3352-d_can";
						clocks = <0x3c>;
						syscon-raminit = <0x06 0x644 0x00>;
						clock-names = "fck";
						status = "disabled";
						interrupts = <0x34>;
						phandle = <0xc4>;
						reg = <0x00 0x2000>;
					};
				};

				target-module@9c000 {
					compatible = "ti,sysc-omap2\0ti,sysc";
					clocks = <0x34 0x0c 0x00>;
					reg-names = "rev\0sysc\0syss";
					ti,syss-mask = <0x01>;
					clock-names = "fck";
					ti,sysc-mask = <0x307>;
					ranges = <0x00 0x9c000 0x1000>;
					#address-cells = <0x01>;
					#size-cells = <0x01>;
					ti,sysc-sidle = <0x00 0x01 0x02 0x03>;
					reg = <0x9c000 0x08 0x9c010 0x08 0x9c090 0x08>;

					i2c@0 {
						compatible = "ti,omap4-i2c";
						symlink = "bone/i2c/2";
						status = "okay";
						#address-cells = <0x01>;
						interrupts = <0x1e>;
						#size-cells = <0x00>;
						phandle = <0xb4>;
						reg = <0x00 0x1000>;
						clock-frequency = <0x186a0>;
						pinctrl-0 = <0x3a>;
						pinctrl-names = "default";

						eeprom@54 {
							compatible = "atmel,24c256";
							phandle = <0xb5>;
							reg = <0x54>;

							nvmem-layout {
								compatible = "fixed-layout";
								#address-cells = <0x01>;
								#size-cells = <0x01>;

								cape_data@0 {
									phandle = <0xb6>;
									reg = <0x00 0x100>;
								};
							};
						};

						eeprom@57 {
							compatible = "atmel,24c256";
							phandle = <0xbb>;
							reg = <0x57>;

							nvmem-layout {
								compatible = "fixed-layout";
								#address-cells = <0x01>;
								#size-cells = <0x01>;

								cape_data@0 {
									phandle = <0xbc>;
									reg = <0x00 0x100>;
								};
							};
						};

						eeprom@55 {
							compatible = "atmel,24c256";
							phandle = <0xb7>;
							reg = <0x55>;

							nvmem-layout {
								compatible = "fixed-layout";
								#address-cells = <0x01>;
								#size-cells = <0x01>;

								cape_data@0 {
									phandle = <0xb8>;
									reg = <0x00 0x100>;
								};
							};
						};

						eeprom@56 {
							compatible = "atmel,24c256";
							phandle = <0xb9>;
							reg = <0x56>;

							nvmem-layout {
								compatible = "fixed-layout";
								#address-cells = <0x01>;
								#size-cells = <0x01>;

								cape_data@0 {
									phandle = <0xba>;
									reg = <0x00 0x100>;
								};
							};
						};
					};
				};

				target-module@8e000 {
					compatible = "ti,sysc";
					ranges = <0x00 0x8e000 0x1000>;
					status = "disabled";
					#address-cells = <0x01>;
					#size-cells = <0x01>;
				};

				target-module@aa000 {
					compatible = "ti,sysc-omap2\0ti,sysc";
					clocks = <0x34 0x00 0x00>;
					reg-names = "rev\0sysc\0syss";
					clock-names = "fck";
					ti,sysc-mask = <0x07>;
					ranges = <0x00 0xaa000 0x1000>;
					#address-cells = <0x01>;
					#size-cells = <0x01>;
					ti,sysc-sidle = <0x00 0x01 0x02 0x03>;
					reg = <0xaa050 0x04 0xaa054 0x04 0xaa058 0x04>;

					serial@0 {
						compatible = "ti,am3352-uart\0ti,omap3-uart";
						status = "disabled";
						interrupts = <0x2e>;
						phandle = <0xc0>;
						reg = <0x00 0x1000>;
						clock-frequency = <0x2dc6c00>;
					};
				};

				target-module@a4000 {
					compatible = "ti,sysc";
					ranges = <0x00 0xa4000 0x1000>;
					status = "disabled";
					#address-cells = <0x01>;
					#size-cells = <0x01>;
				};

				target-module@d0000 {
					compatible = "ti,sysc-omap4\0ti,sysc";
					clocks = <0x34 0x8c 0x00 0x3d>;
					reg-names = "rev";
					clock-names = "fck\0osc";
					ranges = <0x00 0xd0000 0x2000>;
					#address-cells = <0x01>;
					#size-cells = <0x01>;
					reg = <0xd0020 0x04>;

					can@0 {
						compatible = "ti,am3352-d_can";
						clocks = <0x3d>;
						symlink = "bone/can/1";
						syscon-raminit = <0x06 0x644 0x01>;
						clock-names = "fck";
						status = "disabled";
						interrupts = <0x37>;
						phandle = <0xc5>;
						reg = <0x00 0x2000>;
						pinctrl-0 = <0x3e>;
						pinctrl-names = "default";
					};
				};

				target-module@ac000 {
					compatible = "ti,sysc-omap2\0ti,sysc";
					clocks = <0x34 0x78 0x00 0x34 0x78 0x12>;
					reg-names = "rev\0sysc\0syss";
					ti,syss-mask = <0x01>;
					clock-names = "fck\0dbclk";
					ti,sysc-mask = <0x07>;
					ranges = <0x00 0xac000 0x1000>;
					#address-cells = <0x01>;
					#size-cells = <0x01>;
					ti,sysc-sidle = <0x00 0x01 0x02 0x03>;
					reg = <0xac000 0x04 0xac010 0x04 0xac114 0x04>;

					gpio@0 {
						compatible = "ti,omap4-gpio";
						gpio-line-names = "P9_15B\0P8_18\0P8_7\0P8_8\0P8_10\0P8_9\0P8_45 [hdmi]\0P8_46 [hdmi]\0P8_43 [hdmi]\0P8_44 [hdmi]\0P8_41 [hdmi]\0P8_42 [hdmi]\0P8_39 [hdmi]\0P8_40 [hdmi]\0P8_37 [hdmi]\0P8_38 [hdmi]\0P8_36 [hdmi]\0P8_34 [hdmi]\0[rmii1_rxd3]\0[rmii1_rxd2]\0[rmii1_rxd1]\0[rmii1_rxd0]\0P8_27 [hdmi]\0P8_29 [hdmi]\0P8_28 [hdmi]\0P8_30 [hdmi]\0[mmc0_dat3]\0[mmc0_dat2]\0[mmc0_dat1]\0[mmc0_dat0]\0[mmc0_clk]\0[mmc0_cmd]";
						gpio-controller;
						gpio-ranges = <0x23 0x00 0x22 0x12 0x23 0x12 0x4d 0x04 0x23 0x16 0x38 0x0a>;
						#interrupt-cells = <0x02>;
						interrupts = <0x20>;
						phandle = <0xc1>;
						reg = <0x00 0x1000>;
						#gpio-cells = <0x02>;
						interrupt-controller;
					};
				};
			};

			segment@300000 {
				compatible = "simple-pm-bus";
				ranges = <0x00 0x300000 0x1000 0x1000 0x301000 0x1000 0x2000 0x302000 0x1000 0x3000 0x303000 0x1000 0x4000 0x304000 0x1000 0x5000 0x305000 0x1000 0xe000 0x30e000 0x1000 0xf000 0x30f000 0x1000 0x18000 0x318000 0x4000 0x1c000 0x31c000 0x1000 0x10000 0x310000 0x2000 0x12000 0x312000 0x1000 0x15000 0x315000 0x1000 0x16000 0x316000 0x1000 0x17000 0x317000 0x1000 0x13000 0x313000 0x1000 0x14000 0x314000 0x1000 0x20000 0x320000 0x1000 0x21000 0x321000 0x1000 0x22000 0x322000 0x1000 0x23000 0x323000 0x1000 0x24000 0x324000 0x1000 0x25000 0x325000 0x1000>;
				#address-cells = <0x01>;
				#size-cells = <0x01>;

				target-module@e000 {
					ti,sysc-midle = <0x00 0x01 0x02>;
					compatible = "ti,sysc-omap4\0ti,sysc";
					clocks = <0x46 0x00 0x00>;
					reg-names = "rev\0sysc";
					clock-names = "fck";
					ranges = <0x00 0xe000 0x1000>;
					#address-cells = <0x01>;
					#size-cells = <0x01>;
					ti,sysc-sidle = <0x00 0x01 0x02>;
					reg = <0xe000 0x04 0xe054 0x04>;

					lcdc@0 {
						compatible = "ti,am33xx-tilcdc";
						status = "disabled";
						interrupts = <0x24>;
						phandle = <0xd3>;
						reg = <0x00 0x1000>;
					};
				};

				target-module@22000 {
					compatible = "ti,sysc";
					ranges = <0x00 0x22000 0x1000>;
					status = "disabled";
					#address-cells = <0x01>;
					#size-cells = <0x01>;
				};

				target-module@2000 {
					ti,sysc-midle = <0x00 0x01 0x02 0x03>;
					compatible = "ti,sysc-omap4\0ti,sysc";
					clocks = <0x34 0x94 0x00>;
					reg-names = "rev\0sysc";
					clock-names = "fck";
					ranges = <0x00 0x2000 0x1000>;
					#address-cells = <0x01>;
					#size-cells = <0x01>;
					ti,sysc-sidle = <0x00 0x01 0x02 0x03>;
					reg = <0x2000 0x04 0x2004 0x04>;

					epwmss@0 {
						compatible = "ti,am33xx-pwmss";
						ranges = <0x00 0x00 0x1000>;
						status = "disabled";
						#address-cells = <0x01>;
						#size-cells = <0x01>;
						phandle = <0xcb>;
						reg = <0x00 0x10>;

						pwm@100 {
							compatible = "ti,am3352-ecap";
							clocks = <0x2d>;
							clock-names = "fck";
							status = "disabled";
							phandle = <0xcc>;
							reg = <0x100 0x80>;
							#pwm-cells = <0x03>;
						};

						counter@180 {
							compatible = "ti,am3352-eqep";
							clocks = <0x2d>;
							clock-names = "sysclkout";
							status = "disabled";
							interrupts = <0x58>;
							phandle = <0xcd>;
							reg = <0x180 0x80>;
						};

						pwm@200 {
							compatible = "ti,am3352-ehrpwm";
							clocks = <0x44 0x2d>;
							clock-names = "tbclk\0fck";
							status = "disabled";
							phandle = <0xce>;
							reg = <0x200 0x80>;
							#pwm-cells = <0x03>;
						};
					};
				};

				target-module@0 {
					ti,sysc-midle = <0x00 0x01 0x02 0x03>;
					compatible = "ti,sysc-omap4\0ti,sysc";
					clocks = <0x34 0x9c 0x00>;
					reg-names = "rev\0sysc";
					clock-names = "fck";
					ranges = <0x00 0x00 0x1000>;
					#address-cells = <0x01>;
					#size-cells = <0x01>;
					ti,sysc-sidle = <0x00 0x01 0x02 0x03>;
					reg = <0x00 0x04 0x04 0x04>;

					epwmss@0 {
						compatible = "ti,am33xx-pwmss";
						ranges = <0x00 0x00 0x1000>;
						status = "disabled";
						#address-cells = <0x01>;
						#size-cells = <0x01>;
						phandle = <0xc7>;
						reg = <0x00 0x10>;

						pwm@100 {
							compatible = "ti,am3352-ecap";
							clocks = <0x2d>;
							clock-names = "fck";
							status = "disabled";
							phandle = <0xc8>;
							reg = <0x100 0x80>;
							#pwm-cells = <0x03>;
						};

						counter@180 {
							compatible = "ti,am3352-eqep";
							clocks = <0x2d>;
							clock-names = "sysclkout";
							status = "disabled";
							interrupts = <0x4f>;
							phandle = <0xc9>;
							reg = <0x180 0x80>;
						};

						pwm@200 {
							compatible = "ti,am3352-ehrpwm";
							clocks = <0x43 0x2d>;
							clock-names = "tbclk\0fck";
							status = "disabled";
							phandle = <0xca>;
							reg = <0x200 0x80>;
							#pwm-cells = <0x03>;
						};
					};
				};

				target-module@24000 {
					compatible = "ti,sysc";
					ranges = <0x00 0x24000 0x1000>;
					status = "disabled";
					#address-cells = <0x01>;
					#size-cells = <0x01>;
				};

				target-module@4000 {
					ti,sysc-midle = <0x00 0x01 0x02 0x03>;
					compatible = "ti,sysc-omap4\0ti,sysc";
					clocks = <0x34 0xa0 0x00>;
					reg-names = "rev\0sysc";
					clock-names = "fck";
					ranges = <0x00 0x4000 0x1000>;
					#address-cells = <0x01>;
					#size-cells = <0x01>;
					ti,sysc-sidle = <0x00 0x01 0x02 0x03>;
					reg = <0x4000 0x04 0x4004 0x04>;

					epwmss@0 {
						compatible = "ti,am33xx-pwmss";
						ranges = <0x00 0x00 0x1000>;
						status = "disabled";
						#address-cells = <0x01>;
						#size-cells = <0x01>;
						phandle = <0xcf>;
						reg = <0x00 0x10>;

						pwm@100 {
							compatible = "ti,am3352-ecap";
							clocks = <0x2d>;
							clock-names = "fck";
							status = "disabled";
							phandle = <0xd0>;
							reg = <0x100 0x80>;
							#pwm-cells = <0x03>;
						};

						counter@180 {
							compatible = "ti,am3352-eqep";
							clocks = <0x2d>;
							clock-names = "sysclkout";
							status = "disabled";
							interrupts = <0x59>;
							phandle = <0xd1>;
							reg = <0x180 0x80>;
						};

						pwm@200 {
							compatible = "ti,am3352-ehrpwm";
							clocks = <0x45 0x2d>;
							clock-names = "tbclk\0fck";
							status = "disabled";
							phandle = <0xd2>;
							reg = <0x200 0x80>;
							#pwm-cells = <0x03>;
						};
					};
				};

				target-module@13000 {
					compatible = "ti,sysc";
					ranges = <0x00 0x13000 0x1000>;
					status = "disabled";
					#address-cells = <0x01>;
					#size-cells = <0x01>;
				};

				target-module@10000 {
					compatible = "ti,sysc-omap2\0ti,sysc";
					clocks = <0x34 0x58 0x00>;
					reg-names = "rev\0sysc";
					clock-names = "fck";
					ti,sysc-mask = <0x01>;
					ranges = <0x00 0x10000 0x2000>;
					#address-cells = <0x01>;
					#size-cells = <0x01>;
					ti,sysc-sidle = <0x00 0x01>;
					reg = <0x11fe0 0x04 0x11fe4 0x04>;

					rng@0 {
						compatible = "ti,omap4-rng";
						interrupts = <0x6f>;
						phandle = <0xd4>;
						reg = <0x00 0x2000>;
					};
				};

				target-module@20000 {
					compatible = "ti,sysc";
					ranges = <0x00 0x20000 0x1000>;
					status = "disabled";
					#address-cells = <0x01>;
					#size-cells = <0x01>;
				};

				target-module@18000 {
					compatible = "ti,sysc";
					ranges = <0x00 0x18000 0x4000>;
					status = "disabled";
					#address-cells = <0x01>;
					#size-cells = <0x01>;
				};

				target-module@15000 {
					compatible = "ti,sysc";
					ranges = <0x00 0x15000 0x1000 0x1000 0x16000 0x1000>;
					status = "disabled";
					#address-cells = <0x01>;
					#size-cells = <0x01>;
				};
			};

			segment@0 {
				compatible = "simple-pm-bus";
				ranges = <0x00 0x00 0x800 0x800 0x800 0x800 0x1000 0x1000 0x400 0x1400 0x1400 0x400 0x1800 0x1800 0x400 0x1c00 0x1c00 0x400 0x8000 0x8000 0x1000 0x9000 0x9000 0x1000 0x16000 0x16000 0x1000 0x17000 0x17000 0x1000 0x22000 0x22000 0x1000 0x23000 0x23000 0x1000 0x24000 0x24000 0x1000 0x25000 0x25000 0x1000 0x2a000 0x2a000 0x1000 0x2b000 0x2b000 0x1000 0x38000 0x38000 0x2000 0x3a000 0x3a000 0x1000 0x14000 0x14000 0x1000 0x15000 0x15000 0x1000 0x3c000 0x3c000 0x2000 0x3e000 0x3e000 0x1000 0x40000 0x40000 0x1000 0x41000 0x41000 0x1000 0x42000 0x42000 0x1000 0x43000 0x43000 0x1000 0x44000 0x44000 0x1000 0x45000 0x45000 0x1000 0x46000 0x46000 0x1000 0x47000 0x47000 0x1000 0x48000 0x48000 0x1000 0x49000 0x49000 0x1000 0x4c000 0x4c000 0x1000 0x4d000 0x4d000 0x1000 0x50000 0x50000 0x2000 0x52000 0x52000 0x1000 0x60000 0x60000 0x1000 0x61000 0x61000 0x1000 0x80000 0x80000 0x10000 0x90000 0x90000 0x1000 0xa0000 0xa0000 0x10000 0xb0000 0xb0000 0x1000 0x30000 0x30000 0x1000 0x31000 0x31000 0x1000 0x4a000 0x4a000 0x1000 0x4b000 0x4b000 0x1000 0xc8000 0xc8000 0x1000 0xc9000 0xc9000 0x1000 0xcc000 0xcc000 0x1000 0xcd000 0xcd000 0x1000 0xca000 0xca000 0x1000 0xcb000 0xcb000 0x1000 0x46000000 0x46000000 0x400000 0x46400000 0x46400000 0x400000>;
				#address-cells = <0x01>;
				#size-cells = <0x01>;

				target-module@a0000 {
					compatible = "ti,sysc";
					ranges = <0x00 0xa0000 0x10000>;
					status = "disabled";
					#address-cells = <0x01>;
					#size-cells = <0x01>;
				};

				target-module@30000 {
					compatible = "ti,sysc-omap2\0ti,sysc";
					clocks = <0x34 0x14 0x00>;
					reg-names = "rev\0sysc\0syss";
					ti,syss-mask = <0x01>;
					clock-names = "fck";
					ti,sysc-mask = <0x303>;
					ranges = <0x00 0x30000 0x1000>;
					#address-cells = <0x01>;
					#size-cells = <0x01>;
					ti,sysc-sidle = <0x00 0x01 0x02>;
					reg = <0x30000 0x04 0x30110 0x04 0x30114 0x04>;

					spi@0 {
						compatible = "ti,omap4-mcspi";
						status = "disabled";
						#address-cells = <0x01>;
						interrupts = <0x41>;
						#size-cells = <0x00>;
						dma-names = "tx0\0rx0\0tx1\0rx1";
						phandle = <0xa7>;
						reg = <0x00 0x400>;
						dmas = <0x24 0x10 0x00 0x24 0x11 0x00 0x24 0x12 0x00 0x24 0x13 0x00>;
						ti,spi-num-cs = <0x02>;
					};
				};

				target-module@ca000 {
					compatible = "ti,sysc-omap2\0ti,sysc";
					clocks = <0x34 0xd4 0x00>;
					reg-names = "rev\0sysc\0syss";
					ti,syss-mask = <0x01>;
					clock-names = "fck";
					ti,sysc-mask = <0x307>;
					ranges = <0x00 0xca000 0x1000>;
					#address-cells = <0x01>;
					#size-cells = <0x01>;
					ti,sysc-sidle = <0x00 0x01 0x02>;
					reg = <0xca000 0x04 0xca010 0x04 0xca014 0x04>;

					spinlock@0 {
						compatible = "ti,omap4-hwspinlock";
						#hwlock-cells = <0x01>;
						phandle = <0xb3>;
						reg = <0x00 0x1000>;
					};
				};

				target-module@8000 {
					compatible = "ti,sysc";
					ranges = <0x00 0x8000 0x1000>;
					status = "disabled";
					#address-cells = <0x01>;
					#size-cells = <0x01>;
				};

				target-module@22000 {
					compatible = "ti,sysc-omap2\0ti,sysc";
					clocks = <0x34 0x34 0x00>;
					reg-names = "rev\0sysc\0syss";
					clock-names = "fck";
					ti,sysc-mask = <0x07>;
					ranges = <0x00 0x22000 0x1000>;
					#address-cells = <0x01>;
					#size-cells = <0x01>;
					ti,sysc-sidle = <0x00 0x01 0x02 0x03>;
					reg = <0x22050 0x04 0x22054 0x04 0x22058 0x04>;

					serial@0 {
						compatible = "ti,am3352-uart\0ti,omap3-uart";
						status = "disabled";
						interrupts = <0x49>;
						dma-names = "tx\0rx";
						phandle = <0xa4>;
						reg = <0x00 0x1000>;
						clock-frequency = <0x2dc6c00>;
						dmas = <0x24 0x1c 0x00 0x24 0x1d 0x00>;
					};
				};

				target-module@4c000 {
					compatible = "ti,sysc-omap2\0ti,sysc";
					clocks = <0x34 0x74 0x00 0x34 0x74 0x12>;
					reg-names = "rev\0sysc\0syss";
					ti,syss-mask = <0x01>;
					clock-names = "fck\0dbclk";
					ti,sysc-mask = <0x07>;
					ranges = <0x00 0x4c000 0x1000>;
					#address-cells = <0x01>;
					#size-cells = <0x01>;
					ti,sysc-sidle = <0x00 0x01 0x02 0x03>;
					reg = <0x4c000 0x04 0x4c010 0x04 0x4c114 0x04>;

					gpio@0 {
						compatible = "ti,omap4-gpio";
						gpio-line-names = "P8_25 [mmc1_dat0]\0[mmc1_dat1]\0P8_5 [mmc1_dat2]\0P8_6 [mmc1_dat3]\0P8_23 [mmc1_dat4]\0P8_22 [mmc1_dat5]\0P8_3 [mmc1_dat6]\0P8_4 [mmc1_dat7]\0NC\0NC\0NC\0NC\0P8_12\0P8_11\0P8_16\0P8_15\0P9_15A\0P9_23\0P9_14 [ehrpwm1a]\0P9_16 [ehrpwm1b]\0[emmc rst]\0[usr0 led]\0[usr1 led]\0[usr2 led]\0[usr3 led]\0[hdmi irq]\0[usb vbus oc]\0[hdmi audio]\0P9_12\0P8_26\0P8_21 [emmc]\0P8_20 [emmc]";
						gpio-controller;
						gpio-ranges = <0x23 0x00 0x00 0x08 0x23 0x08 0x5a 0x04 0x23 0x0c 0x0c 0x10 0x23 0x1c 0x1e 0x04>;
						#interrupt-cells = <0x02>;
						interrupts = <0x62>;
						phandle = <0x51>;
						reg = <0x00 0x1000>;
						#gpio-cells = <0x02>;
						interrupt-controller;
					};
				};

				target-module@14000 {
					compatible = "ti,sysc";
					ranges = <0x00 0x14000 0x1000>;
					status = "disabled";
					#address-cells = <0x01>;
					#size-cells = <0x01>;
				};

				target-module@46000 {
					compatible = "ti,sysc-omap4-timer\0ti,sysc";
					clocks = <0x34 0xb4 0x00>;
					reg-names = "rev\0sysc\0syss";
					clock-names = "fck";
					ti,sysc-mask = <0x01>;
					ranges = <0x00 0x46000 0x1000>;
					#address-cells = <0x01>;
					#size-cells = <0x01>;
					ti,sysc-sidle = <0x00 0x01 0x02 0x03>;
					reg = <0x46000 0x04 0x46010 0x04 0x46014 0x04>;

					timer@0 {
						compatible = "ti,am335x-timer";
						ti,timer-pwm;
						interrupts = <0x5d>;
						phandle = <0xae>;
						reg = <0x00 0x400>;
					};
				};

				target-module@40000 {
					compatible = "ti,sysc-omap4-timer\0ti,sysc";
					clocks = <0x34 0x48 0x00 0x34 0x28 0x00>;
					reg-names = "rev\0sysc\0syss";
					ti,no-reset-on-init;
					clock-names = "fck\0ick";
					ti,no-idle;
					ti,sysc-mask = <0x01>;
					ranges = <0x00 0x40000 0x1000>;
					#address-cells = <0x01>;
					#size-cells = <0x01>;
					ti,sysc-sidle = <0x00 0x01 0x02 0x03>;
					phandle = <0xaa>;
					reg = <0x40000 0x04 0x40010 0x04 0x40014 0x04>;

					timer@0 {
						assigned-clock-parents = <0x0d>;
						compatible = "ti,am335x-timer";
						clocks = <0x36>;
						clock-names = "fck";
						interrupts = <0x44>;
						assigned-clocks = <0x36>;
						phandle = <0xab>;
						reg = <0x00 0x400>;
					};
				};

				target-module@2a000 {
					compatible = "ti,sysc-omap2\0ti,sysc";
					clocks = <0x34 0x10 0x00>;
					reg-names = "rev\0sysc\0syss";
					ti,syss-mask = <0x01>;
					clock-names = "fck";
					ti,sysc-mask = <0x307>;
					ranges = <0x00 0x2a000 0x1000>;
					#address-cells = <0x01>;
					#size-cells = <0x01>;
					ti,sysc-sidle = <0x00 0x01 0x02 0x03>;
					reg = <0x2a000 0x08 0x2a010 0x08 0x2a090 0x08>;

					i2c@0 {
						compatible = "ti,omap4-i2c";
						status = "disabled";
						#address-cells = <0x01>;
						interrupts = <0x47>;
						#size-cells = <0x00>;
						phandle = <0xa6>;
						reg = <0x00 0x1000>;
					};
				};

				target-module@38000 {
					compatible = "ti,sysc-omap4-simple\0ti,sysc";
					clocks = <0x35 0x18 0x00>;
					reg-names = "rev\0sysc";
					clock-names = "fck";
					ranges = <0x00 0x38000 0x2000 0x46000000 0x46000000 0x400000>;
					#address-cells = <0x01>;
					#size-cells = <0x01>;
					ti,sysc-sidle = <0x00 0x01 0x02>;
					reg = <0x38000 0x04 0x38004 0x04>;

					mcasp@0 {
						compatible = "ti,am33xx-mcasp-audio";
						reg-names = "mpu\0dat";
						status = "disabled";
						interrupts = <0x50 0x51>;
						dma-names = "tx\0rx";
						phandle = <0xa8>;
						reg = <0x00 0x2000 0x46000000 0x400000>;
						dmas = <0x24 0x08 0x02 0x24 0x09 0x02>;
						interrupt-names = "tx\0rx";
					};
				};

				target-module@80000 {
					compatible = "ti,sysc-omap2\0ti,sysc";
					clocks = <0x34 0x08 0x00>;
					reg-names = "rev\0sysc\0syss";
					ti,syss-mask = <0x01>;
					clock-names = "fck";
					ti,sysc-mask = <0x303>;
					ranges = <0x00 0x80000 0x10000>;
					#address-cells = <0x01>;
					#size-cells = <0x01>;
					ti,sysc-sidle = <0x00 0x01 0x02>;
					reg = <0x80000 0x04 0x80010 0x04 0x80014 0x04>;

					elm@0 {
						compatible = "ti,am3352-elm";
						status = "disabled";
						interrupts = <0x04>;
						phandle = <0xb2>;
						reg = <0x00 0x2000>;
					};
				};

				target-module@cc000 {
					compatible = "ti,sysc";
					ranges = <0x00 0xcc000 0x1000>;
					status = "disabled";
					#address-cells = <0x01>;
					#size-cells = <0x01>;
				};

				target-module@24000 {
					compatible = "ti,sysc-omap2\0ti,sysc";
					clocks = <0x34 0x38 0x00>;
					reg-names = "rev\0sysc\0syss";
					clock-names = "fck";
					ti,sysc-mask = <0x07>;
					ranges = <0x00 0x24000 0x1000>;
					#address-cells = <0x01>;
					#size-cells = <0x01>;
					ti,sysc-sidle = <0x00 0x01 0x02 0x03>;
					reg = <0x24050 0x04 0x24054 0x04 0x24058 0x04>;

					serial@0 {
						compatible = "ti,am3352-uart\0ti,omap3-uart";
						status = "disabled";
						interrupts = <0x4a>;
						dma-names = "tx\0rx";
						phandle = <0xa5>;
						reg = <0x00 0x1000>;
						clock-frequency = <0x2dc6c00>;
						dmas = <0x24 0x1e 0x00 0x24 0x1f 0x00>;
					};
				};

				target-module@16000 {
					compatible = "ti,sysc";
					ranges = <0x00 0x16000 0x1000>;
					status = "disabled";
					#address-cells = <0x01>;
					#size-cells = <0x01>;
				};

				target-module@50000 {
					compatible = "ti,sysc";
					ranges = <0x00 0x50000 0x2000>;
					status = "disabled";
					#address-cells = <0x01>;
					#size-cells = <0x01>;
				};

				target-module@48000 {
					compatible = "ti,sysc-omap4-timer\0ti,sysc";
					clocks = <0x34 0xb8 0x00>;
					reg-names = "rev\0sysc\0syss";
					clock-names = "fck";
					ti,sysc-mask = <0x01>;
					ranges = <0x00 0x48000 0x1000>;
					#address-cells = <0x01>;
					#size-cells = <0x01>;
					ti,sysc-sidle = <0x00 0x01 0x02 0x03>;
					reg = <0x48000 0x04 0x48010 0x04 0x48014 0x04>;

					timer@0 {
						compatible = "ti,am335x-timer";
						ti,timer-pwm;
						interrupts = <0x5e>;
						phandle = <0xaf>;
						reg = <0x00 0x400>;
					};
				};

				target-module@42000 {
					compatible = "ti,sysc-omap4-timer\0ti,sysc";
					clocks = <0x34 0x4c 0x00>;
					reg-names = "rev\0sysc\0syss";
					clock-names = "fck";
					ti,sysc-mask = <0x01>;
					ranges = <0x00 0x42000 0x1000>;
					#address-cells = <0x01>;
					#size-cells = <0x01>;
					ti,sysc-sidle = <0x00 0x01 0x02 0x03>;
					reg = <0x42000 0x04 0x42010 0x04 0x42014 0x04>;

					timer@0 {
						compatible = "ti,am335x-timer";
						interrupts = <0x45>;
						phandle = <0xac>;
						reg = <0x00 0x400>;
					};
				};

				target-module@c8000 {
					compatible = "ti,sysc-omap4\0ti,sysc";
					clocks = <0x34 0xd8 0x00>;
					reg-names = "rev\0sysc";
					clock-names = "fck";
					ti,sysc-mask = <0x01>;
					ranges = <0x00 0xc8000 0x1000>;
					#address-cells = <0x01>;
					#size-cells = <0x01>;
					ti,sysc-sidle = <0x00 0x01 0x02>;
					reg = <0xc8000 0x04 0xc8010 0x04>;

					mailbox@0 {
						compatible = "ti,omap4-mailbox";
						ti,mbox-num-users = <0x04>;
						ti,mbox-num-fifos = <0x08>;
						#mbox-cells = <0x01>;
						interrupts = <0x4d>;
						phandle = <0x2f>;
						reg = <0x00 0x200>;

						mbox-wkup-m3 {
							ti,mbox-send-noirq;
							ti,mbox-tx = <0x00 0x00 0x00>;
							ti,mbox-rx = <0x00 0x00 0x03>;
							phandle = <0x30>;
						};
					};
				};

				target-module@60000 {
					compatible = "ti,sysc-omap2\0ti,sysc";
					clocks = <0x34 0x04 0x00>;
					reg-names = "rev\0sysc\0syss";
					ti,syss-mask = <0x01>;
					clock-names = "fck";
					ti,sysc-mask = <0x307>;
					ranges = <0x00 0x60000 0x1000>;
					#address-cells = <0x01>;
					#size-cells = <0x01>;
					ti,sysc-sidle = <0x00 0x01 0x02>;
					reg = <0x602fc 0x04 0x60110 0x04 0x60114 0x04>;

					mmc@0 {
						compatible = "ti,am335-sdhci";
						cd-gpios = <0x38 0x06 0x01>;
						status = "okay";
						interrupts = <0x40>;
						bus-width = <0x04>;
						ti,needs-special-reset;
						dma-names = "tx\0rx";
						phandle = <0xb1>;
						reg = <0x00 0x1000>;
						pinctrl-0 = <0x37>;
						dmas = <0x24 0x18 0x00 0x24 0x19 0x00>;
						vmmc-supply = <0x39>;
						pinctrl-names = "default";
					};
				};

				target-module@4a000 {
					compatible = "ti,sysc-omap4-timer\0ti,sysc";
					clocks = <0x34 0x44 0x00>;
					reg-names = "rev\0sysc\0syss";
					clock-names = "fck";
					ti,sysc-mask = <0x01>;
					ranges = <0x00 0x4a000 0x1000>;
					#address-cells = <0x01>;
					#size-cells = <0x01>;
					ti,sysc-sidle = <0x00 0x01 0x02 0x03>;
					reg = <0x4a000 0x04 0x4a010 0x04 0x4a014 0x04>;

					timer@0 {
						compatible = "ti,am335x-timer";
						ti,timer-pwm;
						interrupts = <0x5f>;
						phandle = <0xb0>;
						reg = <0x00 0x400>;
					};
				};

				target-module@3c000 {
					compatible = "ti,sysc-omap4-simple\0ti,sysc";
					clocks = <0x35 0x4c 0x00>;
					reg-names = "rev\0sysc";
					clock-names = "fck";
					ranges = <0x00 0x3c000 0x2000 0x46400000 0x46400000 0x400000>;
					#address-cells = <0x01>;
					#size-cells = <0x01>;
					ti,sysc-sidle = <0x00 0x01 0x02>;
					reg = <0x3c000 0x04 0x3c004 0x04>;

					mcasp@0 {
						compatible = "ti,am33xx-mcasp-audio";
						reg-names = "mpu\0dat";
						status = "disabled";
						interrupts = <0x52 0x53>;
						dma-names = "tx\0rx";
						phandle = <0xa9>;
						reg = <0x00 0x2000 0x46400000 0x400000>;
						dmas = <0x24 0x0a 0x02 0x24 0x0b 0x02>;
						interrupt-names = "tx\0rx";
					};
				};

				target-module@44000 {
					compatible = "ti,sysc-omap4-timer\0ti,sysc";
					clocks = <0x34 0x50 0x00>;
					reg-names = "rev\0sysc\0syss";
					clock-names = "fck";
					ti,sysc-mask = <0x01>;
					ranges = <0x00 0x44000 0x1000>;
					#address-cells = <0x01>;
					#size-cells = <0x01>;
					ti,sysc-sidle = <0x00 0x01 0x02 0x03>;
					reg = <0x44000 0x04 0x44010 0x04 0x44014 0x04>;

					timer@0 {
						compatible = "ti,am335x-timer";
						ti,timer-pwm;
						interrupts = <0x5c>;
						phandle = <0xad>;
						reg = <0x00 0x400>;
					};
				};
			};

			segment@200000 {
				compatible = "simple-pm-bus";
				ranges = <0x00 0x200000 0x10000>;
				#address-cells = <0x01>;
				#size-cells = <0x01>;

				target-module@0 {
					power-domains = <0x3f>;
					compatible = "ti,sysc-omap4-simple\0ti,sysc";
					clocks = <0x40 0x04 0x00>;
					clock-names = "fck";
					ti,no-idle;
					ranges = <0x00 0x00 0x10000>;
					#address-cells = <0x01>;
					#size-cells = <0x01>;

					mpu@0 {
						compatible = "ti,omap3-mpu";
						pm-sram = <0x41 0x42>;
					};
				};
			};
		};

		target-module@53500000 {
			compatible = "ti,sysc-omap2\0ti,sysc";
			clocks = <0x07 0x70 0x00>;
			reg-names = "rev\0sysc\0syss";
			ti,syss-mask = <0x01>;
			clock-names = "fck";
			ti,sysc-mask = <0x03>;
			ranges = <0x00 0x53500000 0x1000>;
			#address-cells = <0x01>;
			#size-cells = <0x01>;
			ti,sysc-sidle = <0x00 0x01 0x02 0x03>;
			phandle = <0xf3>;
			reg = <0x53500080 0x04 0x53500084 0x04 0x53500088 0x04>;

			aes@0 {
				compatible = "ti,omap4-aes";
				status = "okay";
				interrupts = <0x67>;
				dma-names = "tx\0rx";
				phandle = <0xf4>;
				reg = <0x00 0xa0>;
				dmas = <0x24 0x06 0x00 0x24 0x05 0x00>;
			};
		};

		target-module@49000000 {
			compatible = "ti,sysc-omap4\0ti,sysc";
			clocks = <0x07 0x98 0x00>;
			reg-names = "rev";
			clock-names = "fck";
			ranges = <0x00 0x49000000 0x10000>;
			#address-cells = <0x01>;
			#size-cells = <0x01>;
			reg = <0x49000000 0x04>;

			dma@0 {
				#dma-cells = <0x02>;
				compatible = "ti,edma3-tpcc";
				dma-requests = <0x40>;
				reg-names = "edma3_cc";
				ti,tptcs = <0x54 0x07 0x55 0x05 0x56 0x00>;
				interrupts = <0x0c 0x0d 0x0e>;
				phandle = <0x24>;
				reg = <0x00 0x10000>;
				interrupt-names = "edma3_ccint\0edma3_mperr\0edma3_ccerrint";
				ti,edma-memcpy-channels = <0x14 0x15>;
			};
		};

		interconnect@4a000000 {
			power-domains = <0x09>;
			compatible = "ti,am33xx-l4-fast\0simple-pm-bus";
			clocks = <0x47 0x00 0x00>;
			reg-names = "ap\0la\0ia0";
			clock-names = "fck";
			ranges = <0x00 0x4a000000 0x1000000>;
			#address-cells = <0x01>;
			#size-cells = <0x01>;
			phandle = <0xd6>;
			reg = <0x4a000000 0x800 0x4a000800 0x800 0x4a001000 0x400>;

			segment@0 {
				compatible = "simple-pm-bus";
				ranges = <0x00 0x00 0x800 0x800 0x800 0x800 0x1000 0x1000 0x400 0x100000 0x100000 0x8000 0x108000 0x108000 0x1000 0x180000 0x180000 0x20000 0x1a0000 0x1a0000 0x1000 0x200000 0x200000 0x80000 0x280000 0x280000 0x1000 0x300000 0x300000 0x80000 0x380000 0x380000 0x1000>;
				#address-cells = <0x01>;
				#size-cells = <0x01>;

				target-module@200000 {
					compatible = "ti,sysc";
					ranges = <0x00 0x200000 0x80000>;
					status = "disabled";
					#address-cells = <0x01>;
					#size-cells = <0x01>;
				};

				target-module@100000 {
					ti,sysc-midle = <0x00 0x01>;
					compatible = "ti,sysc-omap4-simple\0ti,sysc";
					clocks = <0x48 0x14 0x00>;
					reg-names = "rev\0sysc\0syss";
					ti,syss-mask = <0x01>;
					clock-names = "fck";
					ti,sysc-mask = <0x00>;
					ranges = <0x00 0x100000 0x8000>;
					#address-cells = <0x01>;
					#size-cells = <0x01>;
					ti,sysc-sidle = <0x00 0x01>;
					reg = <0x101200 0x04 0x101208 0x04 0x101204 0x04>;

					ethernet@0 {
						compatible = "ti,am335x-cpsw\0ti,cpsw";
						clocks = <0x49 0x4a>;
						ale_entries = <0x400>;
						clock-names = "fck\0cpts";
						ranges = <0x00 0x00 0x8000>;
						active_slave = <0x00>;
						bd_ram_size = <0x2000>;
						status = "disabled";
						#address-cells = <0x01>;
						interrupts = <0x28 0x29 0x2a 0x2b>;
						#size-cells = <0x01>;
						cpts_clock_mult = <0x80000000>;
						phandle = <0xd7>;
						reg = <0x00 0x800 0x1200 0x100>;
						slaves = <0x02>;
						syscon = <0x06>;
						cpts_clock_shift = <0x1d>;
						cpdma_channels = <0x08>;
						mac_control = <0x20>;

						slave@300 {
							mac-address = [00 00 00 00 00 00];
							phandle = <0xda>;
							phys = <0x4b 0x02 0x01>;
						};

						slave@200 {
							mac-address = [00 00 00 00 00 00];
							phandle = <0xd9>;
							phys = <0x4b 0x01 0x01>;
						};

						mdio@1000 {
							compatible = "ti,cpsw-mdio\0ti,davinci_mdio";
							clocks = <0x48 0x14 0x00>;
							clock-names = "fck";
							status = "disabled";
							#address-cells = <0x01>;
							#size-cells = <0x00>;
							phandle = <0xd8>;
							reg = <0x1000 0x100>;
							bus_freq = <0xf4240>;
						};
					};

					switch@0 {
						compatible = "ti,am335x-cpsw-switch\0ti,cpsw-switch";
						clocks = <0x49>;
						pinctrl-1 = <0x4d>;
						clock-names = "fck";
						ranges = <0x00 0x00 0x4000>;
						status = "okay";
						#address-cells = <0x01>;
						interrupts = <0x28 0x29 0x2a 0x2b>;
						#size-cells = <0x01>;
						phandle = <0xdb>;
						reg = <0x00 0x4000>;
						pinctrl-0 = <0x4c>;
						syscon = <0x06>;
						interrupt-names = "rx_thresh\0rx\0tx\0misc";
						pinctrl-names = "default\0sleep";

						ethernet-ports {
							#address-cells = <0x01>;
							#size-cells = <0x00>;

							port@1 {
								phy-handle = <0x4e>;
								mac-address = [b0 d5 cc fb ee 22];
								local-mac-address = [b0 d5 cc fb ee 22];
								ti,dual-emac-pvid = <0x01>;
								label = "port1";
								phandle = <0xdc>;
								phys = <0x4b 0x01 0x01>;
								reg = <0x01>;
								phy-mode = "mii";
							};

							port@2 {
								mac-address = [b0 d5 cc fb ee 24];
								local-mac-address = [b0 d5 cc fb ee 24];
								status = "disabled";
								label = "port2";
								phandle = <0xdd>;
								phys = <0x4b 0x02 0x01>;
								reg = <0x02>;
							};
						};

						mdio@1000 {
							compatible = "ti,cpsw-mdio\0ti,davinci_mdio";
							clocks = <0x49>;
							pinctrl-1 = <0x50>;
							clock-names = "fck";
							#address-cells = <0x01>;
							#size-cells = <0x00>;
							phandle = <0xde>;
							reg = <0x1000 0x100>;
							pinctrl-0 = <0x4f>;
							bus_freq = <0xf4240>;
							pinctrl-names = "default\0sleep";

							ethernet-phy@0 {
								reset-assert-us = <0x12c>;
								reset-deassert-us = <0xc350>;
								smsc,disable-energy-detect;
								reset-gpios = <0x51 0x08 0x01>;
								phandle = <0x4e>;
								reg = <0x00>;
							};
						};

						cpts {
							clocks = <0x4a>;
							clock-names = "cpts";
						};
					};
				};

				target-module@180000 {
					compatible = "ti,sysc";
					ranges = <0x00 0x180000 0x20000>;
					status = "disabled";
					#address-cells = <0x01>;
					#size-cells = <0x01>;
				};

				target-module@300000 {
					ti,sysc-midle = <0x00 0x01 0x02>;
					compatible = "ti,sysc-pruss\0ti,sysc";
					clocks = <0x52 0x00 0x00>;
					resets = <0x09 0x01>;
					reg-names = "rev\0sysc";
					clock-names = "fck";
					ti,sysc-mask = <0x30>;
					ranges = <0x00 0x300000 0x80000>;
					status = "okay";
					#address-cells = <0x01>;
					#size-cells = <0x01>;
					ti,sysc-sidle = <0x00 0x01 0x02>;
					phandle = <0xdf>;
					reg = <0x326000 0x04 0x326004 0x04>;
					reset-names = "rstctrl";

					pruss@0 {
						compatible = "ti,am3356-pruss";
						ranges;
						#address-cells = <0x01>;
						#size-cells = <0x01>;
						phandle = <0xe0>;
						reg = <0x00 0x80000>;

						mdio@32400 {
							compatible = "ti,davinci_mdio";
							clocks = <0x16>;
							clock-names = "fck";
							status = "disabled";
							#address-cells = <0x01>;
							#size-cells = <0x00>;
							phandle = <0xe8>;
							reg = <0x32400 0x90>;
							bus_freq = <0xf4240>;
						};

						cfg@26000 {
							compatible = "ti,pruss-cfg\0syscon";
							ranges = <0x00 0x26000 0x2000>;
							#address-cells = <0x01>;
							#size-cells = <0x01>;
							phandle = <0xe2>;
							reg = <0x26000 0x2000>;

							clocks {
								#address-cells = <0x01>;
								#size-cells = <0x00>;

								iepclk-mux@30 {
									clocks = <0x17 0x53>;
									#clock-cells = <0x00>;
									phandle = <0xe3>;
									reg = <0x30>;
								};
							};
						};

						mii-rt@32000 {
							compatible = "ti,pruss-mii\0syscon";
							phandle = <0xe4>;
							reg = <0x32000 0x58>;
						};

						pru@38000 {
							compatible = "ti,am3356-pru";
							reg-names = "iram\0control\0debug";
							phandle = <0xe7>;
							reg = <0x38000 0x2000 0x24000 0x400 0x24400 0x100>;
							firmware-name = "am335x-pru1-fw";
						};

						interrupt-controller@20000 {
							compatible = "ti,pruss-intc";
							#interrupt-cells = <0x03>;
							interrupts = <0x14 0x15 0x16 0x17 0x18 0x19 0x1a 0x1b>;
							phandle = <0xe5>;
							reg = <0x20000 0x2000>;
							interrupt-names = "host_intr0\0host_intr1\0host_intr2\0host_intr3\0host_intr4\0host_intr5\0host_intr6\0host_intr7";
							interrupt-controller;
						};

						pru@34000 {
							compatible = "ti,am3356-pru";
							reg-names = "iram\0control\0debug";
							phandle = <0xe6>;
							reg = <0x34000 0x2000 0x22000 0x400 0x22400 0x100>;
							firmware-name = "am335x-pru0-fw";
						};

						memories@0 {
							reg-names = "dram0\0dram1\0shrdram2";
							phandle = <0xe1>;
							reg = <0x00 0x2000 0x2000 0x2000 0x10000 0x3000>;
						};
					};
				};
			};
		};

		target-module@49a00000 {
			ti,sysc-midle = <0x00>;
			compatible = "ti,sysc-omap4\0ti,sysc";
			clocks = <0x07 0xdc 0x00>;
			reg-names = "rev\0sysc";
			clock-names = "fck";
			ti,sysc-mask = <0x01>;
			ranges = <0x00 0x49a00000 0x100000>;
			#address-cells = <0x01>;
			#size-cells = <0x01>;
			ti,sysc-sidle = <0x00 0x02>;
			reg = <0x49a00000 0x04 0x49a00010 0x04>;

			dma@0 {
				compatible = "ti,edma3-tptc";
				interrupts = <0x72>;
				phandle = <0x56>;
				reg = <0x00 0x100000>;
				interrupt-names = "edma3_tcerrint";
			};
		};

		target-module@47810000 {
			compatible = "ti,sysc-omap2\0ti,sysc";
			clocks = <0x35 0xdc 0x00>;
			reg-names = "rev\0sysc\0syss";
			ti,syss-mask = <0x01>;
			clock-names = "fck";
			ti,sysc-mask = <0x307>;
			ranges = <0x00 0x47810000 0x1000>;
			#address-cells = <0x01>;
			#size-cells = <0x01>;
			ti,sysc-sidle = <0x00 0x01 0x02>;
			reg = <0x478102fc 0x04 0x47810110 0x04 0x47810114 0x04>;

			mmc@0 {
				compatible = "ti,am335-sdhci";
				status = "disabled";
				interrupts = <0x1d>;
				ti,needs-special-reset;
				phandle = <0xea>;
				reg = <0x00 0x1000>;
			};
		};

		interconnect@4b140000 {
			compatible = "ti,am33xx-l4-mpuss\0simple-bus";
			reg-names = "la\0ap";
			ranges = <0x00 0x4b140000 0x8000>;
			#address-cells = <0x01>;
			#size-cells = <0x01>;
			phandle = <0xe9>;
			reg = <0x4b144400 0x100 0x4b144800 0x400>;

			segment@0 {
				compatible = "simple-bus";
				ranges = <0x4800 0x4800 0x400 0x1000 0x1000 0x1000 0x2000 0x2000 0x1000 0x4000 0x4000 0x400 0x5000 0x5000 0x400 0x00 0x00 0x1000 0x3000 0x3000 0x1000 0x800 0x800 0x800>;
				#address-cells = <0x01>;
				#size-cells = <0x01>;

				target-module@0 {
					compatible = "ti,sysc";
					ranges = <0x00 0x00 0x1000 0x1000 0x1000 0x1000 0x2000 0x2000 0x1000>;
					status = "disabled";
					#address-cells = <0x01>;
					#size-cells = <0x01>;
				};

				target-module@3000 {
					compatible = "ti,sysc";
					ranges = <0x00 0x3000 0x1000>;
					status = "disabled";
					#address-cells = <0x01>;
					#size-cells = <0x01>;
				};
			};
		};

		target-module@40300000 {
			compatible = "ti,sysc-omap4-simple\0ti,sysc";
			clocks = <0x07 0x08 0x00>;
			clock-names = "fck";
			ti,no-idle;
			ranges = <0x00 0x40300000 0x10000>;
			#address-cells = <0x01>;
			#size-cells = <0x01>;

			sram@0 {
				compatible = "mmio-sram";
				ranges = <0x00 0x00 0x10000>;
				#address-cells = <0x01>;
				#size-cells = <0x01>;
				phandle = <0xee>;
				reg = <0x00 0x10000>;

				pm-data-sram@1000 {
					compatible = "ti,sram";
					phandle = <0x42>;
					reg = <0x1000 0x1000>;
					pool;
				};

				pm-code-sram@0 {
					compatible = "ti,sram";
					phandle = <0x41>;
					reg = <0x00 0x1000>;
					protect-exec;
				};
			};
		};

		interconnect@44c00000 {
			power-domains = <0x0a>;
			compatible = "ti,am33xx-l4-wkup\0simple-pm-bus";
			clocks = <0x0b 0x0c 0x00>;
			reg-names = "ap\0la\0ia0\0ia1";
			clock-names = "fck";
			ranges = <0x00 0x44c00000 0x100000 0x100000 0x44d00000 0x100000 0x200000 0x44e00000 0x100000>;
			#address-cells = <0x01>;
			#size-cells = <0x01>;
			phandle = <0x61>;
			reg = <0x44c00000 0x800 0x44c00800 0x800 0x44c01000 0x400 0x44c01400 0x400>;

			segment@100000 {
				compatible = "simple-pm-bus";
				ranges = <0x00 0x100000 0x4000 0x4000 0x104000 0x1000 0x80000 0x180000 0x2000 0x82000 0x182000 0x1000>;
				#address-cells = <0x01>;
				#size-cells = <0x01>;

				target-module@0 {
					compatible = "ti,sysc-omap4\0ti,sysc";
					clocks = <0x0c 0x00 0x00>;
					reg-names = "rev";
					clock-names = "fck";
					ranges = <0x00 0x00 0x4000 0x80000 0x80000 0x2000>;
					#address-cells = <0x01>;
					#size-cells = <0x01>;
					reg = <0x00 0x04>;

					cpu@0 {
						ti,pm-firmware = "am335x-pm-firmware.elf";
						compatible = "ti,am3352-wkup-m3";
						resets = <0x0a 0x03>;
						reg-names = "umem\0dmem";
						phandle = <0x2e>;
						reg = <0x00 0x4000 0x80000 0x2000>;
						reset-names = "rstctrl";
					};
				};
			};

			segment@0 {
				compatible = "simple-pm-bus";
				ranges = <0x00 0x00 0x800 0x800 0x800 0x800 0x1000 0x1000 0x400 0x1400 0x1400 0x400>;
				#address-cells = <0x01>;
				#size-cells = <0x01>;
			};

			segment@200000 {
				compatible = "simple-pm-bus";
				ranges = <0x00 0x200000 0x2000 0x2000 0x202000 0x1000 0x3000 0x203000 0x1000 0x4000 0x204000 0x1000 0x5000 0x205000 0x1000 0x6000 0x206000 0x1000 0x7000 0x207000 0x1000 0x8000 0x208000 0x1000 0x9000 0x209000 0x1000 0xa000 0x20a000 0x1000 0xb000 0x20b000 0x1000 0xc000 0x20c000 0x1000 0xd000 0x20d000 0x1000 0xf000 0x20f000 0x1000 0x10000 0x210000 0x10000 0x20000 0x220000 0x10000 0x30000 0x230000 0x1000 0x31000 0x231000 0x1000 0x32000 0x232000 0x1000 0x33000 0x233000 0x1000 0x34000 0x234000 0x1000 0x35000 0x235000 0x1000 0x36000 0x236000 0x1000 0x37000 0x237000 0x1000 0x38000 0x238000 0x1000 0x39000 0x239000 0x1000 0x3a000 0x23a000 0x1000 0x3e000 0x23e000 0x1000 0x3f000 0x23f000 0x1000 0xe000 0x20e000 0x1000 0x40000 0x240000 0x40000 0x80000 0x280000 0x1000>;
				#address-cells = <0x01>;
				#size-cells = <0x01>;

				target-module@39000 {
					compatible = "ti,sysc";
					ranges = <0x00 0x39000 0x1000>;
					status = "disabled";
					#address-cells = <0x01>;
					#size-cells = <0x01>;
				};

				target-module@b000 {
					compatible = "ti,sysc-omap2\0ti,sysc";
					clocks = <0x0b 0xb8 0x00>;
					reg-names = "rev\0sysc\0syss";
					ti,syss-mask = <0x01>;
					clock-names = "fck";
					ti,sysc-mask = <0x307>;
					ranges = <0x00 0xb000 0x1000>;
					#address-cells = <0x01>;
					#size-cells = <0x01>;
					ti,sysc-sidle = <0x00 0x01 0x02 0x03>;
					reg = <0xb000 0x08 0xb010 0x08 0xb090 0x08>;

					i2c@0 {
						compatible = "ti,omap4-i2c";
						symlink = "bone/i2c/0";
						status = "okay";
						#address-cells = <0x01>;
						interrupts = <0x46>;
						#size-cells = <0x00>;
						phandle = <0x88>;
						reg = <0x00 0x1000>;
						clock-frequency = <0x61a80>;
						pinctrl-0 = <0x26>;
						pinctrl-names = "default";

						eeprom@50 {
							compatible = "atmel,24c32";
							vcc-supply = <0x27>;
							phandle = <0x8e>;
							reg = <0x50>;

							nvmem-layout {
								compatible = "fixed-layout";
								#address-cells = <0x01>;
								#size-cells = <0x01>;

								baseboard_data@0 {
									phandle = <0x8f>;
									reg = <0x00 0x100>;
								};
							};
						};

						pmic@24 {
							compatible = "ti,tps65217";
							ti,pmic-shutdown-controller;
							#interrupt-cells = <0x01>;
							interrupt-parent = <0x01>;
							interrupts = <0x07>;
							phandle = <0x5a>;
							reg = <0x24>;
							interrupt-controller;

							charger {
								compatible = "ti,tps65217-charger";
								status = "okay";
								interrupts = <0x00 0x01>;
								interrupt-names = "USB\0AC";
							};

							regulators {
								#address-cells = <0x01>;
								#size-cells = <0x00>;

								regulator@3 {
									phandle = <0x8b>;
									regulator-compatible = "ldo1";
									reg = <0x03>;
									regulator-always-on;
									regulator-name = "vio,vrtc,vdds";
								};

								regulator@1 {
									regulator-boot-on;
									phandle = <0x05>;
									regulator-compatible = "dcdc2";
									regulator-min-microvolt = <0xe1d48>;
									reg = <0x01>;
									regulator-max-microvolt = <0x149f4c>;
									regulator-always-on;
									regulator-name = "vdd_mpu";
								};

								regulator@6 {
									phandle = <0x27>;
									regulator-compatible = "ldo4";
									reg = <0x06>;
									regulator-always-on;
									regulator-name = "vdd_3v3a";
								};

								regulator@4 {
									phandle = <0x8c>;
									regulator-compatible = "ldo2";
									reg = <0x04>;
									regulator-always-on;
									regulator-name = "vdd_3v3aux";
								};

								regulator@2 {
									regulator-boot-on;
									phandle = <0x8a>;
									regulator-compatible = "dcdc3";
									regulator-min-microvolt = <0xe1d48>;
									reg = <0x02>;
									regulator-max-microvolt = <0x118c30>;
									regulator-always-on;
									regulator-name = "vdd_core";
								};

								regulator@0 {
									phandle = <0x89>;
									regulator-compatible = "dcdc1";
									reg = <0x00>;
									regulator-always-on;
									regulator-name = "vdds_dpr";
								};

								regulator@5 {
									phandle = <0x8d>;
									regulator-compatible = "ldo3";
									regulator-min-microvolt = <0x1b7740>;
									reg = <0x05>;
									regulator-max-microvolt = <0x1b7740>;
									regulator-always-on;
									regulator-name = "vdd_1v8";
								};
							};

							pwrbutton {
								compatible = "ti,tps65217-pwrbutton";
								status = "okay";
								interrupts = <0x02>;
							};
						};
					};
				};

				target-module@33000 {
					compatible = "ti,sysc";
					ranges = <0x00 0x33000 0x1000>;
					status = "disabled";
					#address-cells = <0x01>;
					#size-cells = <0x01>;
				};

				target-module@5000 {
					compatible = "ti,sysc";
					ranges = <0x00 0x5000 0x1000>;
					status = "disabled";
					#address-cells = <0x01>;
					#size-cells = <0x01>;
				};

				target-module@0 {
					compatible = "ti,sysc-omap4\0ti,sysc";
					reg-names = "rev";
					ranges = <0x00 0x00 0x2000>;
					#address-cells = <0x01>;
					#size-cells = <0x01>;
					reg = <0x00 0x04>;

					prcm@0 {
						compatible = "ti,am3-prcm\0simple-bus";
						ranges = <0x00 0x00 0x2000>;
						#address-cells = <0x01>;
						#size-cells = <0x01>;
						phandle = <0x62>;
						reg = <0x00 0x2000>;

						clocks {
							#address-cells = <0x01>;
							#size-cells = <0x00>;
							phandle = <0x63>;

							clock@52c {
								compatible = "ti,clksel";
								#address-cells = <0x01>;
								#size-cells = <0x00>;
								#clock-cells = <0x02>;
								reg = <0x52c>;

								clock-gfx-fclk-clksel@1 {
									compatible = "ti,mux-clock";
									clocks = <0x16 0x14>;
									#clock-cells = <0x00>;
									phandle = <0x1f>;
									reg = <0x01>;
									clock-output-names = "gfx_fclk_clksel_ck";
								};

								clock-gfx-fck-div@0 {
									compatible = "ti,divider-clock";
									clocks = <0x1f>;
									ti,max-div = <0x02>;
									#clock-cells = <0x00>;
									phandle = <0x7a>;
									reg = <0x00>;
									clock-output-names = "gfx_fck_div_ck";
								};
							};

							clock-l4ls-gclk {
								compatible = "fixed-factor-clock";
								clocks = <0x1d>;
								clock-mult = <0x01>;
								#clock-cells = <0x00>;
								phandle = <0x2d>;
								clock-output-names = "l4ls_gclk";
								clock-div = <0x01>;
							};

							clock-cpsw-cpts-rft@520 {
								compatible = "ti,mux-clock";
								clocks = <0x1e 0x16>;
								#clock-cells = <0x00>;
								phandle = <0x4a>;
								reg = <0x520>;
								clock-output-names = "cpsw_cpts_rft_clk";
							};

							clock-dpll-per-m2-div4-wkupdm {
								compatible = "fixed-factor-clock";
								clocks = <0x14>;
								clock-mult = <0x01>;
								#clock-cells = <0x00>;
								phandle = <0x67>;
								clock-output-names = "dpll_per_m2_div4_wkupdm_ck";
								clock-div = <0x04>;
							};

							clock-dpll-per-m2@4ac {
								compatible = "ti,divider-clock";
								clocks = <0x13>;
								ti,max-div = <0x1f>;
								ti,index-starts-at-one;
								#clock-cells = <0x00>;
								phandle = <0x14>;
								reg = <0x4ac>;
								clock-output-names = "dpll_per_m2_ck";
							};

							clock-mmc {
								compatible = "fixed-factor-clock";
								clocks = <0x14>;
								clock-mult = <0x01>;
								#clock-cells = <0x00>;
								phandle = <0x79>;
								clock-output-names = "mmc_clk";
								clock-div = <0x02>;
							};

							clock-pruss-ocp-gclk@530 {
								compatible = "ti,mux-clock";
								clocks = <0x17 0x18>;
								#clock-cells = <0x00>;
								phandle = <0x53>;
								reg = <0x530>;
								clock-output-names = "pruss_ocp_gclk";
							};

							clock-dpll-core-x2 {
								compatible = "ti,am3-dpll-x2-clock";
								clocks = <0x0e>;
								#clock-cells = <0x00>;
								phandle = <0x0f>;
								clock-output-names = "dpll_core_x2_ck";
							};

							clock@48c {
								compatible = "ti,am3-dpll-no-gate-j-type-clock";
								clocks = <0x0d 0x0d>;
								#clock-cells = <0x00>;
								phandle = <0x13>;
								reg = <0x48c 0x470 0x49c 0x474 0x478>;
								clock-output-names = "dpll_per_ck";
							};

							clock-virt-19200000 {
								compatible = "fixed-clock";
								#clock-cells = <0x00>;
								phandle = <0x29>;
								clock-output-names = "virt_19200000_ck";
								clock-frequency = <0x124f800>;
							};

							clock-dpll-ddr-m2-div2 {
								compatible = "fixed-factor-clock";
								clocks = <0x11>;
								clock-mult = <0x01>;
								#clock-cells = <0x00>;
								phandle = <0x66>;
								clock-output-names = "dpll_ddr_m2_div2_ck";
								clock-div = <0x02>;
							};

							clock@700 {
								compatible = "ti,clksel";
								#address-cells = <0x01>;
								#size-cells = <0x00>;
								#clock-cells = <0x02>;
								reg = <0x700>;

								clock-sysclkout-pre@0 {
									compatible = "ti,mux-clock";
									clocks = <0x1c 0x17 0x11 0x14 0x20>;
									#clock-cells = <0x00>;
									phandle = <0x21>;
									reg = <0x00>;
									clock-output-names = "sysclkout_pre_ck";
								};

								clock-clkout2-div@3 {
									compatible = "ti,divider-clock";
									clocks = <0x21>;
									ti,max-div = <0x08>;
									#clock-cells = <0x00>;
									phandle = <0x22>;
									reg = <0x03>;
									clock-output-names = "clkout2_div_ck";
								};

								clock-clkout2@7 {
									compatible = "ti,gate-clock";
									clocks = <0x22>;
									#clock-cells = <0x00>;
									phandle = <0x7b>;
									reg = <0x07>;
									clock-output-names = "clkout2_ck";
								};
							};

							clock-timer1-fck@528 {
								compatible = "ti,mux-clock";
								clocks = <0x0d 0x19 0x00 0x00 0x1a 0x1b 0x1c>;
								#clock-cells = <0x00>;
								phandle = <0x31>;
								reg = <0x528>;
								clock-output-names = "timer1_fck";
							};

							clock-virt-26000000 {
								compatible = "fixed-clock";
								#clock-cells = <0x00>;
								phandle = <0x2c>;
								clock-output-names = "virt_26000000_ck";
								clock-frequency = <0x18cba80>;
							};

							clock-timer7-fck@504 {
								compatible = "ti,mux-clock";
								clocks = <0x1a 0x0d 0x19 0x00 0x00>;
								#clock-cells = <0x00>;
								phandle = <0x6f>;
								reg = <0x504>;
								clock-output-names = "timer7_fck";
							};

							clock-clk-24mhz {
								compatible = "fixed-factor-clock";
								clocks = <0x14>;
								clock-mult = <0x01>;
								#clock-cells = <0x00>;
								phandle = <0x15>;
								clock-output-names = "clk_24mhz";
								clock-div = <0x08>;
							};

							clock-l4fw-gclk {
								compatible = "fixed-factor-clock";
								clocks = <0x1d>;
								clock-mult = <0x01>;
								#clock-cells = <0x00>;
								phandle = <0x76>;
								clock-output-names = "l4fw_gclk";
								clock-div = <0x01>;
							};

							clock-l3-gclk {
								compatible = "fixed-factor-clock";
								clocks = <0x16>;
								clock-mult = <0x01>;
								#clock-cells = <0x00>;
								phandle = <0x17>;
								clock-output-names = "l3_gclk";
								clock-div = <0x01>;
							};

							clock-clk-rc32k {
								compatible = "fixed-clock";
								#clock-cells = <0x00>;
								phandle = <0x1b>;
								clock-output-names = "clk_rc32k_ck";
								clock-frequency = <0x7d00>;
							};

							clock-timer6-fck@51c {
								compatible = "ti,mux-clock";
								clocks = <0x1a 0x0d 0x19 0x00 0x00>;
								#clock-cells = <0x00>;
								phandle = <0x6e>;
								reg = <0x51c>;
								clock-output-names = "timer6_fck";
							};

							clock@498 {
								compatible = "ti,am3-dpll-no-gate-clock";
								clocks = <0x0d 0x0d>;
								#clock-cells = <0x00>;
								phandle = <0x12>;
								reg = <0x498 0x448 0x454 0x44c 0x450>;
								clock-output-names = "dpll_disp_ck";
							};

							clock-wdt1-fck@538 {
								compatible = "ti,mux-clock";
								clocks = <0x1b 0x19 0x00 0x00>;
								#clock-cells = <0x00>;
								phandle = <0x72>;
								reg = <0x538>;
								clock-output-names = "wdt1_fck";
							};

							clock-timer5-fck@518 {
								compatible = "ti,mux-clock";
								clocks = <0x1a 0x0d 0x19 0x00 0x00>;
								#clock-cells = <0x00>;
								phandle = <0x6d>;
								reg = <0x518>;
								clock-output-names = "timer5_fck";
							};

							clock@488 {
								compatible = "ti,am3-dpll-clock";
								clocks = <0x0d 0x0d>;
								#clock-cells = <0x00>;
								phandle = <0x03>;
								reg = <0x488 0x420 0x42c 0x424 0x428>;
								clock-output-names = "dpll_mpu_ck";
							};

							clock-dpll-mpu-m2@4a8 {
								compatible = "ti,divider-clock";
								clocks = <0x03>;
								ti,max-div = <0x1f>;
								ti,index-starts-at-one;
								#clock-cells = <0x00>;
								phandle = <0x65>;
								reg = <0x4a8>;
								clock-output-names = "dpll_mpu_m2_ck";
							};

							clock-timer3-fck@50c {
								compatible = "ti,mux-clock";
								clocks = <0x1a 0x0d 0x19 0x00 0x00>;
								#clock-cells = <0x00>;
								phandle = <0x6b>;
								reg = <0x50c>;
								clock-output-names = "timer3_fck";
							};

							clock-virt-24000000 {
								compatible = "fixed-clock";
								#clock-cells = <0x00>;
								phandle = <0x2a>;
								clock-output-names = "virt_24000000_ck";
								clock-frequency = <0x16e3600>;
							};

							clock-timer4-fck@510 {
								compatible = "ti,mux-clock";
								clocks = <0x1a 0x0d 0x19 0x00 0x00>;
								#clock-cells = <0x00>;
								phandle = <0x6c>;
								reg = <0x510>;
								clock-output-names = "timer4_fck";
							};

							clock-l4-rtc-gclk {
								compatible = "fixed-factor-clock";
								clocks = <0x16>;
								clock-mult = <0x01>;
								#clock-cells = <0x00>;
								phandle = <0x73>;
								clock-output-names = "l4_rtc_gclk";
								clock-div = <0x02>;
							};

							clock-dpll-core-m4@480 {
								compatible = "ti,divider-clock";
								clocks = <0x0f>;
								ti,max-div = <0x1f>;
								ti,index-starts-at-one;
								#clock-cells = <0x00>;
								phandle = <0x16>;
								reg = <0x480>;
								clock-output-names = "dpll_core_m4_ck";
							};

							clock-timer2-fck@508 {
								compatible = "ti,mux-clock";
								clocks = <0x1a 0x0d 0x19 0x00 0x00>;
								#clock-cells = <0x00>;
								phandle = <0x36>;
								reg = <0x508>;
								clock-output-names = "timer2_fck";
							};

							clock-l4hs-gclk {
								compatible = "fixed-factor-clock";
								clocks = <0x16>;
								clock-mult = <0x01>;
								#clock-cells = <0x00>;
								phandle = <0x74>;
								clock-output-names = "l4hs_gclk";
								clock-div = <0x01>;
							};

							clock-usbotg-fck-8@47c {
								compatible = "ti,gate-clock";
								clocks = <0x13>;
								#clock-cells = <0x00>;
								phandle = <0x70>;
								reg = <0x47c>;
								clock-output-names = "usbotg_fck";
								ti,bit-shift = <0x08>;
							};

							clock-lcd-gclk@534 {
								compatible = "ti,mux-clock";
								clocks = <0x18 0x1e 0x14>;
								#clock-cells = <0x00>;
								phandle = <0x20>;
								reg = <0x534>;
								clock-output-names = "lcd_gclk";
								ti,set-rate-parent;
							};

							clock-dpll-core-m4-div2 {
								compatible = "fixed-factor-clock";
								clocks = <0x16>;
								clock-mult = <0x01>;
								#clock-cells = <0x00>;
								phandle = <0x1d>;
								clock-output-names = "dpll_core_m4_div2_ck";
								clock-div = <0x02>;
							};

							clock-ieee5000-fck-1@e4 {
								compatible = "ti,gate-clock";
								clocks = <0x1d>;
								#clock-cells = <0x00>;
								phandle = <0x71>;
								reg = <0xe4>;
								clock-output-names = "ieee5000_fck";
								ti,bit-shift = <0x01>;
							};

							clock-dpll-core-m5@484 {
								compatible = "ti,divider-clock";
								clocks = <0x0f>;
								ti,max-div = <0x1f>;
								ti,index-starts-at-one;
								#clock-cells = <0x00>;
								phandle = <0x1e>;
								reg = <0x484>;
								clock-output-names = "dpll_core_m5_ck";
							};

							clock@494 {
								compatible = "ti,am3-dpll-no-gate-clock";
								clocks = <0x0d 0x0d>;
								#clock-cells = <0x00>;
								phandle = <0x10>;
								reg = <0x494 0x434 0x440 0x438 0x43c>;
								clock-output-names = "dpll_ddr_ck";
							};

							clock-mmu-fck-1@914 {
								compatible = "ti,gate-clock";
								clocks = <0x16>;
								#clock-cells = <0x00>;
								phandle = <0x6a>;
								reg = <0x914>;
								clock-output-names = "mmu_fck";
								ti,bit-shift = <0x01>;
							};

							clock-dpll-disp-m2@4a4 {
								compatible = "ti,divider-clock";
								clocks = <0x12>;
								ti,max-div = <0x1f>;
								ti,index-starts-at-one;
								#clock-cells = <0x00>;
								phandle = <0x18>;
								reg = <0x4a4>;
								clock-output-names = "dpll_disp_m2_ck";
								ti,set-rate-parent;
							};

							clock-clkdiv32k {
								compatible = "fixed-factor-clock";
								clocks = <0x15>;
								clock-mult = <0x01>;
								#clock-cells = <0x00>;
								phandle = <0x69>;
								clock-output-names = "clkdiv32k_ck";
								clock-div = <0x2dc>;
							};

							clock-sysclk-div {
								compatible = "fixed-factor-clock";
								clocks = <0x16>;
								clock-mult = <0x01>;
								#clock-cells = <0x00>;
								phandle = <0x77>;
								clock-output-names = "sysclk_div_ck";
								clock-div = <0x01>;
							};

							clock-tclkin {
								compatible = "fixed-clock";
								#clock-cells = <0x00>;
								phandle = <0x1a>;
								clock-output-names = "tclkin_ck";
								clock-frequency = <0xb71b00>;
							};

							clock-dpll-per-m2-div4 {
								compatible = "fixed-factor-clock";
								clocks = <0x14>;
								clock-mult = <0x01>;
								#clock-cells = <0x00>;
								phandle = <0x68>;
								clock-output-names = "dpll_per_m2_div4_ck";
								clock-div = <0x04>;
							};

							clock-dpll-core-m6@4d8 {
								compatible = "ti,divider-clock";
								clocks = <0x0f>;
								ti,max-div = <0x1f>;
								ti,index-starts-at-one;
								#clock-cells = <0x00>;
								phandle = <0x64>;
								reg = <0x4d8>;
								clock-output-names = "dpll_core_m6_ck";
							};

							clock-l3s-gclk {
								compatible = "fixed-factor-clock";
								clocks = <0x1d>;
								clock-mult = <0x01>;
								#clock-cells = <0x00>;
								phandle = <0x75>;
								clock-output-names = "l3s_gclk";
								clock-div = <0x01>;
							};

							clock@490 {
								compatible = "ti,am3-dpll-core-clock";
								clocks = <0x0d 0x0d>;
								#clock-cells = <0x00>;
								phandle = <0x0e>;
								reg = <0x490 0x45c 0x468 0x460 0x464>;
								clock-output-names = "dpll_core_ck";
							};

							clock-gpio0-dbclk-mux@53c {
								compatible = "ti,mux-clock";
								clocks = <0x1b 0x1c 0x19 0x00 0x00>;
								#clock-cells = <0x00>;
								phandle = <0x78>;
								reg = <0x53c>;
								clock-output-names = "gpio0_dbclk_mux_ck";
							};

							clock-clk-32768 {
								compatible = "fixed-clock";
								#clock-cells = <0x00>;
								phandle = <0x1c>;
								clock-output-names = "clk_32768_ck";
								clock-frequency = <0x8000>;
							};

							clock-dpll-ddr-m2@4a0 {
								compatible = "ti,divider-clock";
								clocks = <0x10>;
								ti,max-div = <0x1f>;
								ti,index-starts-at-one;
								#clock-cells = <0x00>;
								phandle = <0x11>;
								reg = <0x4a0>;
								clock-output-names = "dpll_ddr_m2_ck";
							};

							clock-virt-25000000 {
								compatible = "fixed-clock";
								#clock-cells = <0x00>;
								phandle = <0x2b>;
								clock-output-names = "virt_25000000_ck";
								clock-frequency = <0x17d7840>;
							};

							clock-cpsw-125mhz-gclk {
								compatible = "fixed-factor-clock";
								clocks = <0x1e>;
								clock-mult = <0x01>;
								#clock-cells = <0x00>;
								phandle = <0x49>;
								clock-output-names = "cpsw_125mhz_gclk";
								clock-div = <0x02>;
							};
						};

						prm@c00 {
							compatible = "ti,am3-prm-inst\0ti,omap-prm-inst";
							#reset-cells = <0x01>;
							phandle = <0x09>;
							reg = <0xc00 0x100>;
							#power-domain-cells = <0x00>;
						};

						prm@1200 {
							compatible = "ti,am3-prm-inst\0ti,omap-prm-inst";
							phandle = <0x85>;
							reg = <0x1200 0x100>;
							#power-domain-cells = <0x00>;
						};

						clock@400 {
							compatible = "ti,omap4-cm";
							ranges = <0x00 0x400 0x100>;
							#address-cells = <0x01>;
							#size-cells = <0x01>;
							phandle = <0x7e>;
							reg = <0x400 0x100>;
							clock-output-names = "wkup_cm";

							clock@14 {
								compatible = "ti,clkctrl";
								#clock-cells = <0x02>;
								phandle = <0x08>;
								reg = <0x14 0x04>;
								clock-output-names = "l3_aon_clkctrl";
							};

							clock@b0 {
								compatible = "ti,clkctrl";
								#clock-cells = <0x02>;
								phandle = <0x0c>;
								reg = <0xb0 0x04>;
								clock-output-names = "l4_wkup_aon_clkctrl";
							};

							clock@0 {
								compatible = "ti,clkctrl";
								#clock-cells = <0x02>;
								phandle = <0x0b>;
								reg = <0x00 0x10 0xb4 0x24>;
								clock-output-names = "l4_wkup_clkctrl";
							};
						};

						prm@f00 {
							compatible = "ti,am3-prm-inst\0ti,omap-prm-inst";
							#reset-cells = <0x01>;
							phandle = <0x84>;
							reg = <0xf00 0x100>;
						};

						prm@1100 {
							compatible = "ti,am3-prm-inst\0ti,omap-prm-inst";
							#reset-cells = <0x01>;
							phandle = <0x5d>;
							reg = <0x1100 0x100>;
							#power-domain-cells = <0x00>;
						};

						prm@e00 {
							compatible = "ti,am3-prm-inst\0ti,omap-prm-inst";
							phandle = <0x3f>;
							reg = <0xe00 0x100>;
							#power-domain-cells = <0x00>;
						};

						clock@600 {
							compatible = "ti,omap4-cm";
							ranges = <0x00 0x600 0x100>;
							#address-cells = <0x01>;
							#size-cells = <0x01>;
							phandle = <0x7f>;
							reg = <0x600 0x100>;
							clock-output-names = "mpu_cm";

							clock@0 {
								compatible = "ti,clkctrl";
								#clock-cells = <0x02>;
								phandle = <0x40>;
								reg = <0x00 0x08>;
								clock-output-names = "mpu_clkctrl";
							};
						};

						clock@900 {
							compatible = "ti,omap4-cm";
							ranges = <0x00 0x900 0x100>;
							#address-cells = <0x01>;
							#size-cells = <0x01>;
							phandle = <0x81>;
							reg = <0x900 0x100>;
							clock-output-names = "gfx_l3_cm";

							clock@0 {
								compatible = "ti,clkctrl";
								#clock-cells = <0x02>;
								phandle = <0x5c>;
								reg = <0x00 0x08>;
								clock-output-names = "gfx_l3_clkctrl";
							};
						};

						prm@1000 {
							compatible = "ti,am3-prm-inst\0ti,omap-prm-inst";
							phandle = <0x32>;
							reg = <0x1000 0x100>;
							#power-domain-cells = <0x00>;
						};

						prm@d00 {
							compatible = "ti,am3-prm-inst\0ti,omap-prm-inst";
							#reset-cells = <0x01>;
							phandle = <0x0a>;
							reg = <0xd00 0x100>;
							#power-domain-cells = <0x00>;
						};

						clock@a00 {
							compatible = "ti,omap4-cm";
							ranges = <0x00 0xa00 0x100>;
							#address-cells = <0x01>;
							#size-cells = <0x01>;
							phandle = <0x82>;
							reg = <0xa00 0x100>;
							clock-output-names = "l4_cefuse_cm";

							clock@0 {
								compatible = "ti,clkctrl";
								#clock-cells = <0x02>;
								phandle = <0x83>;
								reg = <0x00 0x24>;
								clock-output-names = "l4_cefuse_clkctrl";
							};
						};

						clock@800 {
							compatible = "ti,omap4-cm";
							ranges = <0x00 0x800 0x100>;
							#address-cells = <0x01>;
							#size-cells = <0x01>;
							phandle = <0x80>;
							reg = <0x800 0x100>;
							clock-output-names = "l4_rtc_cm";

							clock@0 {
								compatible = "ti,clkctrl";
								#clock-cells = <0x02>;
								phandle = <0x33>;
								reg = <0x00 0x04>;
								clock-output-names = "l4_rtc_clkctrl";
							};
						};

						clockdomains {
							phandle = <0x7c>;
						};

						clock@0 {
							compatible = "ti,omap4-cm";
							ranges = <0x00 0x00 0x400>;
							#address-cells = <0x01>;
							#size-cells = <0x01>;
							phandle = <0x7d>;
							reg = <0x00 0x400>;
							clock-output-names = "per_cm";

							clock@24 {
								compatible = "ti,clkctrl";
								#clock-cells = <0x02>;
								phandle = <0x07>;
								reg = <0x24 0x0c 0x94 0x10 0xbc 0x04 0xdc 0x08 0xfc 0x08>;
								clock-output-names = "l3_clkctrl";
							};

							clock@14c {
								compatible = "ti,clkctrl";
								#clock-cells = <0x02>;
								phandle = <0x19>;
								reg = <0x14c 0x04>;
								clock-output-names = "clk_24mhz_clkctrl";
							};

							clock@1c {
								compatible = "ti,clkctrl";
								#clock-cells = <0x02>;
								phandle = <0x35>;
								reg = <0x1c 0x04 0x30 0x08 0x68 0x04 0xf8 0x04>;
								clock-output-names = "l3s_clkctrl";
							};

							clock@e8 {
								compatible = "ti,clkctrl";
								#clock-cells = <0x02>;
								phandle = <0x52>;
								reg = <0xe8 0x04>;
								clock-output-names = "pruss_ocp_clkctrl";
							};

							clock@38 {
								compatible = "ti,clkctrl";
								#clock-cells = <0x02>;
								phandle = <0x34>;
								reg = <0x38 0x2c 0x6c 0x28 0xac 0x0c 0xc0 0x1c 0xec 0x0c 0x10c 0x08 0x130 0x04>;
								clock-output-names = "l4ls_clkctrl";
							};

							clock@18 {
								compatible = "ti,clkctrl";
								#clock-cells = <0x02>;
								phandle = <0x46>;
								reg = <0x18 0x04>;
								clock-output-names = "lcdc_clkctrl";
							};

							clock@0 {
								compatible = "ti,clkctrl";
								#clock-cells = <0x02>;
								phandle = <0x48>;
								reg = <0x00 0x18>;
								clock-output-names = "cpsw_125mhz_clkctrl";
							};

							clock@120 {
								compatible = "ti,clkctrl";
								#clock-cells = <0x02>;
								phandle = <0x47>;
								reg = <0x120 0x04>;
								clock-output-names = "l4hs_clkctrl";
							};
						};
					};
				};

				target-module@3e000 {
					power-domains = <0x32>;
					compatible = "ti,sysc-omap4-simple\0ti,sysc";
					clocks = <0x33 0x00 0x00>;
					reg-names = "rev\0sysc";
					clock-names = "fck";
					ranges = <0x00 0x3e000 0x1000>;
					#address-cells = <0x01>;
					#size-cells = <0x01>;
					ti,sysc-sidle = <0x00 0x01 0x02 0x03>;
					reg = <0x3e074 0x04 0x3e078 0x04>;

					rtc@0 {
						compatible = "ti,am3352-rtc\0ti,da830-rtc";
						clocks = <0x1c 0x19 0x00 0x00>;
						clock-names = "ext-clk\0int-clk";
						interrupts = <0x4b 0x4c>;
						system-power-controller;
						phandle = <0xa2>;
						reg = <0x00 0x1000>;
					};
				};

				target-module@40000 {
					compatible = "ti,sysc";
					ranges = <0x00 0x40000 0x40000>;
					status = "disabled";
					#address-cells = <0x01>;
					#size-cells = <0x01>;
				};

				target-module@d000 {
					compatible = "ti,sysc-omap4\0ti,sysc";
					clocks = <0x0b 0xbc 0x00>;
					reg-names = "rev\0sysc";
					clock-names = "fck";
					ranges = <0x00 0xd000 0x1000 0x1000 0xe000 0x1000>;
					#address-cells = <0x01>;
					#size-cells = <0x01>;
					ti,sysc-sidle = <0x00 0x01 0x02 0x03>;
					reg = <0xd000 0x04 0xd010 0x04>;

					tscadc@0 {
						compatible = "ti,am3359-tscadc";
						clocks = <0x28>;
						clock-names = "fck";
						status = "okay";
						interrupts = <0x10>;
						dma-names = "fifo0\0fifo1";
						phandle = <0x90>;
						reg = <0x00 0x1000>;
						dmas = <0x24 0x35 0x00 0x24 0x39 0x00>;

						adc {
							compatible = "ti,am3359-adc";
							ti,chan-step-avg = <0x10 0x10 0x10 0x10 0x10 0x10 0x10 0x10>;
							#io-channel-cells = <0x01>;
							ti,chan-step-sampledelay = <0x00 0x00 0x00 0x00 0x00 0x00 0x00 0x00>;
							phandle = <0x91>;
							ti,adc-channels = <0x00 0x01 0x02 0x03 0x04 0x05 0x06 0x07>;
							ti,chan-step-opendelay = <0x98 0x98 0x98 0x98 0x98 0x98 0x98 0x98>;
						};

						tsc {
							compatible = "ti,am3359-tsc";
						};
					};
				};

				target-module@35000 {
					compatible = "ti,sysc-omap2\0ti,sysc";
					clocks = <0x0b 0xd4 0x00>;
					reg-names = "rev\0sysc\0syss";
					ti,syss-mask = <0x01>;
					clock-names = "fck";
					ti,sysc-mask = <0x22>;
					ranges = <0x00 0x35000 0x1000>;
					#address-cells = <0x01>;
					#size-cells = <0x01>;
					ti,sysc-sidle = <0x00 0x01 0x02 0x03>;
					reg = <0x35000 0x04 0x35010 0x04 0x35014 0x04>;

					wdt@0 {
						compatible = "ti,omap3-wdt";
						interrupts = <0x5b>;
						phandle = <0xa1>;
						reg = <0x00 0x1000>;
					};
				};

				target-module@7000 {
					compatible = "ti,sysc-omap2\0ti,sysc";
					clocks = <0x0b 0x08 0x00 0x0b 0x08 0x12>;
					reg-names = "rev\0sysc\0syss";
					ti,syss-mask = <0x01>;
					clock-names = "fck\0dbclk";
					ti,sysc-mask = <0x07>;
					ranges = <0x00 0x7000 0x1000>;
					#address-cells = <0x01>;
					#size-cells = <0x01>;
					ti,sysc-sidle = <0x00 0x01 0x02 0x03>;
					phandle = <0x86>;
					reg = <0x7000 0x04 0x7010 0x04 0x7114 0x04>;

					gpio@0 {
						compatible = "ti,omap4-gpio";
						gpio-line-names = "[mdio_data]\0[mdio_clk]\0P9_22 [spi0_sclk]\0P9_21 [spi0_d0]\0P9_18 [spi0_d1]\0P9_17 [spi0_cs0]\0[mmc0_cd]\0P9_42A [ecappwm0]\0P8_35 [lcd d12]\0P8_33 [lcd d13]\0P8_31 [lcd d14]\0P8_32 [lcd d15]\0P9_20 [i2c2_sda]\0P9_19 [i2c2_scl]\0P9_26 [uart1_rxd]\0P9_24 [uart1_txd]\0[rmii1_txd3]\0[rmii1_txd2]\0[usb0_drvvbus]\0[hdmi cec]\0P9_41B\0[rmii1_txd1]\0P8_19 [ehrpwm2a]\0P8_13 [ehrpwm2b]\0NC\0NC\0P8_14\0P8_17\0[rmii1_txd0]\0[rmii1_refclk]\0P9_11 [uart4_rxd]\0P9_13 [uart4_txd]";
						gpio-controller;
						gpio-ranges = <0x23 0x00 0x52 0x08 0x23 0x08 0x34 0x04 0x23 0x0c 0x5e 0x04 0x23 0x10 0x47 0x02 0x23 0x12 0x87 0x01 0x23 0x13 0x6c 0x02 0x23 0x15 0x49 0x01 0x23 0x16 0x08 0x02 0x23 0x1a 0x0a 0x02 0x23 0x1c 0x4a 0x01 0x23 0x1d 0x51 0x01 0x23 0x1e 0x1c 0x02>;
						#interrupt-cells = <0x02>;
						interrupts = <0x60>;
						phandle = <0x38>;
						reg = <0x00 0x1000>;
						#gpio-cells = <0x02>;
						interrupt-controller;
					};
				};

				target-module@10000 {
					compatible = "ti,sysc-omap4\0ti,sysc";
					clocks = <0x0b 0x04 0x00>;
					reg-names = "rev";
					clock-names = "fck";
					ti,no-idle;
					ranges = <0x00 0x10000 0x10000 0x10000 0x20000 0x10000>;
					#address-cells = <0x01>;
					#size-cells = <0x01>;
					reg = <0x10000 0x04>;

					scm@0 {
						compatible = "ti,am3-scm\0simple-bus";
						#pinctrl-cells = <0x01>;
						ranges = <0x00 0x00 0x2000>;
						#address-cells = <0x01>;
						#size-cells = <0x01>;
						phandle = <0x92>;
						reg = <0x00 0x2000>;

						scm_conf@0 {
							compatible = "syscon\0simple-bus";
							ranges = <0x00 0x00 0x800>;
							#address-cells = <0x01>;
							#size-cells = <0x01>;
							phandle = <0x06>;
							reg = <0x00 0x800>;

							clocks {
								#address-cells = <0x01>;
								#size-cells = <0x00>;
								phandle = <0x94>;

								clock@664 {
									compatible = "ti,clksel";
									#address-cells = <0x01>;
									#size-cells = <0x00>;
									#clock-cells = <0x02>;
									reg = <0x664>;

									clock-ehrpwm0-tbclk@0 {
										compatible = "ti,gate-clock";
										clocks = <0x2d>;
										#clock-cells = <0x00>;
										phandle = <0x43>;
										reg = <0x00>;
										clock-output-names = "ehrpwm0_tbclk";
									};

									clock-ehrpwm2-tbclk@2 {
										compatible = "ti,gate-clock";
										clocks = <0x2d>;
										#clock-cells = <0x00>;
										phandle = <0x45>;
										reg = <0x02>;
										clock-output-names = "ehrpwm2_tbclk";
									};

									clock-ehrpwm1-tbclk@1 {
										compatible = "ti,gate-clock";
										clocks = <0x2d>;
										#clock-cells = <0x00>;
										phandle = <0x44>;
										reg = <0x01>;
										clock-output-names = "ehrpwm1_tbclk";
									};
								};

								clock-sha0-fck {
									compatible = "fixed-factor-clock";
									clocks = <0x0d>;
									clock-mult = <0x01>;
									#clock-cells = <0x00>;
									phandle = <0x99>;
									clock-output-names = "sha0_fck";
									clock-div = <0x01>;
								};

								clock-smartreflex0-fck {
									compatible = "fixed-factor-clock";
									clocks = <0x0d>;
									clock-mult = <0x01>;
									#clock-cells = <0x00>;
									phandle = <0x97>;
									clock-output-names = "smartreflex0_fck";
									clock-div = <0x01>;
								};

								clock-adc-tsc-fck {
									compatible = "fixed-factor-clock";
									clocks = <0x0d>;
									clock-mult = <0x01>;
									#clock-cells = <0x00>;
									phandle = <0x28>;
									clock-output-names = "adc_tsc_fck";
									clock-div = <0x01>;
								};

								clock-rng-fck {
									compatible = "fixed-factor-clock";
									clocks = <0x0d>;
									clock-mult = <0x01>;
									#clock-cells = <0x00>;
									phandle = <0x9b>;
									clock-output-names = "rng_fck";
									clock-div = <0x01>;
								};

								clock-smartreflex1-fck {
									compatible = "fixed-factor-clock";
									clocks = <0x0d>;
									clock-mult = <0x01>;
									#clock-cells = <0x00>;
									phandle = <0x98>;
									clock-output-names = "smartreflex1_fck";
									clock-div = <0x01>;
								};

								clock-mcasp0-fck {
									compatible = "fixed-factor-clock";
									clocks = <0x0d>;
									clock-mult = <0x01>;
									#clock-cells = <0x00>;
									phandle = <0x95>;
									clock-output-names = "mcasp0_fck";
									clock-div = <0x01>;
								};

								clock-sys-clkin-22@40 {
									compatible = "ti,mux-clock";
									clocks = <0x29 0x2a 0x2b 0x2c>;
									#clock-cells = <0x00>;
									phandle = <0x0d>;
									reg = <0x40>;
									clock-output-names = "sys_clkin_ck";
									ti,bit-shift = <0x16>;
								};

								clock-dcan0-fck {
									compatible = "fixed-factor-clock";
									clocks = <0x0d>;
									clock-mult = <0x01>;
									#clock-cells = <0x00>;
									phandle = <0x3c>;
									clock-output-names = "dcan0_fck";
									clock-div = <0x01>;
								};

								clock-mcasp1-fck {
									compatible = "fixed-factor-clock";
									clocks = <0x0d>;
									clock-mult = <0x01>;
									#clock-cells = <0x00>;
									phandle = <0x96>;
									clock-output-names = "mcasp1_fck";
									clock-div = <0x01>;
								};

								clock-aes0-fck {
									compatible = "fixed-factor-clock";
									clocks = <0x0d>;
									clock-mult = <0x01>;
									#clock-cells = <0x00>;
									phandle = <0x9a>;
									clock-output-names = "aes0_fck";
									clock-div = <0x01>;
								};

								clock-dcan1-fck {
									compatible = "fixed-factor-clock";
									clocks = <0x0d>;
									clock-mult = <0x01>;
									#clock-cells = <0x00>;
									phandle = <0x3d>;
									clock-output-names = "dcan1_fck";
									clock-div = <0x01>;
								};
							};

							phy-gmii-sel {
								compatible = "ti,am3352-phy-gmii-sel";
								phandle = <0x4b>;
								reg = <0x650 0x04>;
								#phy-cells = <0x02>;
							};
						};

						pinmux@800 {
							compatible = "pinctrl-single";
							pinctrl-single,function-mask = <0x7f>;
							pinctrl-single,register-width = <0x20>;
							#pinctrl-cells = <0x02>;
							phandle = <0x23>;
							reg = <0x800 0x238>;

							cpsw-sleep-pins {
								pinctrl-single,pins = <0x110 0x20 0x07 0x114 0x20 0x07 0x118 0x20 0x07 0x11c 0x20 0x07 0x120 0x20 0x07 0x124 0x20 0x07 0x128 0x20 0x07 0x12c 0x20 0x07 0x130 0x20 0x07 0x134 0x20 0x07 0x138 0x20 0x07 0x13c 0x20 0x07 0x140 0x20 0x07>;
								phandle = <0x4d>;
							};

							mmc1-pins {
								pinctrl-single,pins = <0x160 0x28 0x07 0xfc 0x30 0x00 0xf8 0x30 0x00 0xf4 0x30 0x00 0xf0 0x30 0x00 0x104 0x30 0x00 0x100 0x30 0x00>;
								phandle = <0x37>;
							};

							i2c2-pins {
								pinctrl-single,pins = <0x178 0x30 0x03 0x17c 0x30 0x03>;
								phandle = <0x3a>;
							};

							emmc-pins {
								pinctrl-single,pins = <0x80 0x30 0x02 0x84 0x30 0x02 0x00 0x30 0x01 0x04 0x30 0x01 0x08 0x30 0x01 0x0c 0x30 0x01 0x10 0x30 0x01 0x14 0x30 0x01 0x18 0x30 0x01 0x1c 0x30 0x01>;
								phandle = <0x93>;
							};

							davinci-mdio-sleep-pins {
								pinctrl-single,pins = <0x148 0x20 0x07 0x14c 0x20 0x07 0x168 0x20 0x07>;
								phandle = <0x50>;
							};

							pinmux_comms_can_pins {
								pinctrl-single,pins = <0x184 0x32 0x180 0x12>;
								phandle = <0x3e>;
							};

							davinci-mdio-default-pins {
								pinctrl-single,pins = <0x148 0x30 0x00 0x14c 0x10 0x00 0x168 0x10 0x07>;
								phandle = <0x4f>;
							};

							i2c0-pins {
								pinctrl-single,pins = <0x188 0x30 0x00 0x18c 0x30 0x00>;
								phandle = <0x26>;
							};

							uart0-pins {
								pinctrl-single,pins = <0x170 0x30 0x00 0x174 0x00 0x00>;
								phandle = <0x25>;
							};

							user-leds-s0-pins {
								pinctrl-single,pins = <0x54 0x00 0x07 0x58 0x10 0x07 0x5c 0x00 0x07 0x60 0x10 0x07>;
								phandle = <0x5e>;
							};

							cpsw-default-pins {
								pinctrl-single,pins = <0x110 0x30 0x00 0x114 0x00 0x00 0x118 0x30 0x00 0x11c 0x00 0x00 0x120 0x00 0x00 0x124 0x00 0x00 0x128 0x00 0x00 0x12c 0x30 0x00 0x130 0x30 0x00 0x134 0x30 0x00 0x138 0x30 0x00 0x13c 0x30 0x00 0x140 0x30 0x00>;
								phandle = <0x4c>;
							};

							pinmux_comms_rs485_pins {
								pinctrl-single,pins = <0x74 0x0e 0x70 0x2e>;
								phandle = <0x3b>;
							};
						};

						dma-router@f90 {
							#dma-cells = <0x03>;
							compatible = "ti,am335x-edma-crossbar";
							dma-requests = <0x20>;
							dma-masters = <0x24>;
							phandle = <0x9d>;
							reg = <0xf90 0x40>;
						};

						wkup_m3_ipc@1324 {
							compatible = "ti,am3352-wkup-m3-ipc";
							ti,rproc = <0x2e>;
							interrupts = <0x4e>;
							mboxes = <0x2f 0x30>;
							phandle = <0x9c>;
							reg = <0x1324 0x24>;
							firmware-name = "am335x-bone-scale-data.bin";
						};

						control@620 {
							compatible = "ti,am335x-usb-ctrl-module";
							reg-names = "phy_ctrl\0wakeup";
							phandle = <0x57>;
							reg = <0x620 0x10 0x648 0x04>;
						};

						clockdomains {
							phandle = <0x9e>;
						};
					};
				};

				target-module@37000 {
					compatible = "ti,sysc";
					ranges = <0x00 0x37000 0x1000>;
					status = "disabled";
					#address-cells = <0x01>;
					#size-cells = <0x01>;
				};

				target-module@31000 {
					compatible = "ti,sysc-omap2-timer\0ti,sysc";
					clocks = <0x0b 0xc4 0x00 0x0b 0x0c 0x00>;
					reg-names = "rev\0sysc\0syss";
					ti,no-reset-on-init;
					ti,syss-mask = <0x01>;
					clock-names = "fck\0ick";
					ti,no-idle;
					ti,sysc-mask = <0x303>;
					ranges = <0x00 0x31000 0x1000>;
					#address-cells = <0x01>;
					#size-cells = <0x01>;
					ti,sysc-sidle = <0x00 0x01 0x02>;
					phandle = <0x9f>;
					reg = <0x31000 0x04 0x31010 0x04 0x31014 0x04>;

					timer@0 {
						assigned-clock-parents = <0x0d>;
						compatible = "ti,am335x-timer-1ms";
						clocks = <0x31>;
						clock-names = "fck";
						ti,timer-alwon;
						interrupts = <0x43>;
						assigned-clocks = <0x31>;
						phandle = <0xa0>;
						reg = <0x00 0x400>;
					};
				};

				target-module@9000 {
					compatible = "ti,sysc-omap2\0ti,sysc";
					clocks = <0x0b 0xb4 0x00>;
					reg-names = "rev\0sysc\0syss";
					clock-names = "fck";
					ti,sysc-mask = <0x07>;
					ranges = <0x00 0x9000 0x1000>;
					#address-cells = <0x01>;
					#size-cells = <0x01>;
					ti,sysc-sidle = <0x00 0x01 0x02 0x03>;
					reg = <0x9050 0x04 0x9054 0x04 0x9058 0x04>;

					serial@0 {
						compatible = "ti,am3352-uart\0ti,omap3-uart";
						status = "okay";
						interrupts = <0x48>;
						dma-names = "tx\0rx";
						phandle = <0x87>;
						reg = <0x00 0x1000>;
						clock-frequency = <0x2dc6c00>;
						pinctrl-0 = <0x25>;
						dmas = <0x24 0x1a 0x00 0x24 0x1b 0x00>;
						pinctrl-names = "default";
					};
				};

				target-module@3000 {
					compatible = "ti,sysc";
					ranges = <0x00 0x3000 0x1000>;
					status = "disabled";
					#address-cells = <0x01>;
					#size-cells = <0x01>;
				};
			};
		};

		interconnect@47c00000 {
			compatible = "ti,am33xx-l4-fw\0simple-bus";
			reg-names = "ap\0la\0ia0";
			ranges = <0x00 0x47c00000 0x1000000>;
			#address-cells = <0x01>;
			#size-cells = <0x01>;
			phandle = <0xd5>;
			reg = <0x47c00000 0x800 0x47c00800 0x800 0x47c01000 0x400>;

			segment@0 {
				compatible = "simple-bus";
				ranges = <0x00 0x00 0x800 0x800 0x800 0x800 0x1000 0x1000 0x400 0xc000 0xc000 0x1000 0xd000 0xd000 0x1000 0xe000 0xe000 0x1000 0xf000 0xf000 0x1000 0x10000 0x10000 0x1000 0x11000 0x11000 0x1000 0x1a000 0x1a000 0x1000 0x1b000 0x1b000 0x1000 0x24000 0x24000 0x1000 0x25000 0x25000 0x1000 0x26000 0x26000 0x1000 0x27000 0x27000 0x1000 0x30000 0x30000 0x1000 0x31000 0x31000 0x1000 0x38000 0x38000 0x1000 0x39000 0x39000 0x1000 0x3a000 0x3a000 0x1000 0x3b000 0x3b000 0x1000 0x3e000 0x3e000 0x1000 0x3f000 0x3f000 0x1000 0x3c000 0x3c000 0x1000 0x40000 0x40000 0x1000 0x46000 0x46000 0x1000 0x47000 0x47000 0x1000 0x44000 0x44000 0x1000 0x45000 0x45000 0x1000 0x28000 0x28000 0x1000 0x29000 0x29000 0x1000 0x32000 0x32000 0x1000 0x33000 0x33000 0x1000 0x3d000 0x3d000 0x1000 0x41000 0x41000 0x1000 0x42000 0x42000 0x1000 0x43000 0x43000 0x1000 0x14000 0x14000 0x1000 0x15000 0x15000 0x1000>;
				#address-cells = <0x01>;
				#size-cells = <0x01>;

				target-module@e000 {
					compatible = "ti,sysc";
					ranges = <0x00 0xe000 0x1000>;
					status = "disabled";
					#address-cells = <0x01>;
					#size-cells = <0x01>;
				};

				target-module@30000 {
					compatible = "ti,sysc";
					ranges = <0x00 0x30000 0x1000>;
					status = "disabled";
					#address-cells = <0x01>;
					#size-cells = <0x01>;
				};

				target-module@1a000 {
					compatible = "ti,sysc";
					ranges = <0x00 0x1a000 0x1000>;
					status = "disabled";
					#address-cells = <0x01>;
					#size-cells = <0x01>;
				};

				target-module@28000 {
					compatible = "ti,sysc";
					ranges = <0x00 0x28000 0x1000>;
					status = "disabled";
					#address-cells = <0x01>;
					#size-cells = <0x01>;
				};

				target-module@14000 {
					compatible = "ti,sysc";
					ranges = <0x00 0x14000 0x1000>;
					status = "disabled";
					#address-cells = <0x01>;
					#size-cells = <0x01>;
				};

				target-module@3e000 {
					compatible = "ti,sysc";
					ranges = <0x00 0x3e000 0x1000>;
					status = "disabled";
					#address-cells = <0x01>;
					#size-cells = <0x01>;
				};

				target-module@46000 {
					compatible = "ti,sysc";
					ranges = <0x00 0x46000 0x1000>;
					status = "disabled";
					#address-cells = <0x01>;
					#size-cells = <0x01>;
				};

				target-module@40000 {
					compatible = "ti,sysc";
					ranges = <0x00 0x40000 0x1000>;
					status = "disabled";
					#address-cells = <0x01>;
					#size-cells = <0x01>;
				};

				target-module@38000 {
					compatible = "ti,sysc";
					ranges = <0x00 0x38000 0x1000>;
					status = "disabled";
					#address-cells = <0x01>;
					#size-cells = <0x01>;
				};

				target-module@32000 {
					compatible = "ti,sysc";
					ranges = <0x00 0x32000 0x1000>;
					status = "disabled";
					#address-cells = <0x01>;
					#size-cells = <0x01>;
				};

				target-module@24000 {
					compatible = "ti,sysc";
					ranges = <0x00 0x24000 0x1000>;
					status = "disabled";
					#address-cells = <0x01>;
					#size-cells = <0x01>;
				};

				target-module@10000 {
					compatible = "ti,sysc";
					ranges = <0x00 0x10000 0x1000>;
					status = "disabled";
					#address-cells = <0x01>;
					#size-cells = <0x01>;
				};

				target-module@3a000 {
					compatible = "ti,sysc";
					ranges = <0x00 0x3a000 0x1000>;
					status = "disabled";
					#address-cells = <0x01>;
					#size-cells = <0x01>;
				};

				target-module@42000 {
					compatible = "ti,sysc";
					ranges = <0x00 0x42000 0x1000>;
					status = "disabled";
					#address-cells = <0x01>;
					#size-cells = <0x01>;
				};

				target-module@c000 {
					compatible = "ti,sysc";
					ranges = <0x00 0xc000 0x1000>;
					status = "disabled";
					#address-cells = <0x01>;
					#size-cells = <0x01>;
				};

				target-module@26000 {
					compatible = "ti,sysc";
					ranges = <0x00 0x26000 0x1000>;
					status = "disabled";
					#address-cells = <0x01>;
					#size-cells = <0x01>;
				};

				target-module@3c000 {
					compatible = "ti,sysc";
					ranges = <0x00 0x3c000 0x1000>;
					status = "disabled";
					#address-cells = <0x01>;
					#size-cells = <0x01>;
				};

				target-module@44000 {
					compatible = "ti,sysc";
					ranges = <0x00 0x44000 0x1000>;
					status = "disabled";
					#address-cells = <0x01>;
					#size-cells = <0x01>;
				};
			};
		};

		target-module@4c000000 {
			compatible = "ti,sysc-omap4-simple\0ti,sysc";
			clocks = <0x07 0x04 0x00>;
			reg-names = "rev";
			clock-names = "fck";
			ti,no-idle;
			ranges = <0x00 0x4c000000 0x1000000>;
			#address-cells = <0x01>;
			#size-cells = <0x01>;
			reg = <0x4c000000 0x04>;

			emif@0 {
				compatible = "ti,emif-am3352";
				interrupts = <0x65>;
				sram = <0x41 0x42>;
				phandle = <0xef>;
				reg = <0x00 0x1000000>;
			};
		};

		interrupt-controller@48200000 {
			compatible = "ti,am33xx-intc";
			#interrupt-cells = <0x01>;
			phandle = <0x01>;
			reg = <0x48200000 0x1000>;
			interrupt-controller;
		};

		target-module@53100000 {
			compatible = "ti,sysc-omap3-sham\0ti,sysc";
			clocks = <0x07 0x7c 0x00>;
			reg-names = "rev\0sysc\0syss";
			ti,syss-mask = <0x01>;
			clock-names = "fck";
			ti,sysc-mask = <0x03>;
			ranges = <0x00 0x53100000 0x1000>;
			#address-cells = <0x01>;
			#size-cells = <0x01>;
			ti,sysc-sidle = <0x00 0x01 0x02>;
			phandle = <0xf1>;
			reg = <0x53100100 0x04 0x53100110 0x04 0x53100114 0x04>;

			sham@0 {
				compatible = "ti,omap4-sham";
				status = "okay";
				interrupts = <0x6d>;
				dma-names = "rx";
				phandle = <0xf2>;
				reg = <0x00 0x200>;
				dmas = <0x24 0x24 0x00>;
			};
		};

		target-module@49900000 {
			ti,sysc-midle = <0x00>;
			compatible = "ti,sysc-omap4\0ti,sysc";
			clocks = <0x07 0xd8 0x00>;
			reg-names = "rev\0sysc";
			clock-names = "fck";
			ti,sysc-mask = <0x01>;
			ranges = <0x00 0x49900000 0x100000>;
			#address-cells = <0x01>;
			#size-cells = <0x01>;
			ti,sysc-sidle = <0x00 0x02>;
			reg = <0x49900000 0x04 0x49900010 0x04>;

			dma@0 {
				compatible = "ti,edma3-tptc";
				interrupts = <0x71>;
				phandle = <0x55>;
				reg = <0x00 0x100000>;
				interrupt-names = "edma3_tcerrint";
			};
		};

		target-module@50000000 {
			compatible = "ti,sysc-omap2\0ti,sysc";
			clocks = <0x35 0x14 0x00>;
			reg-names = "rev\0sysc\0syss";
			ti,syss-mask = <0x01>;
			clock-names = "fck";
			ranges = <0x50000000 0x50000000 0x1000 0x00 0x00 0x40000000>;
			#address-cells = <0x01>;
			#size-cells = <0x01>;
			ti,sysc-sidle = <0x00 0x01 0x02>;
			reg = <0x50000000 0x04 0x50000010 0x04 0x50000014 0x04>;

			gpmc@50000000 {
				compatible = "ti,am3352-gpmc";
				gpio-controller;
				gpmc,num-waitpins = <0x02>;
				status = "disabled";
				#interrupt-cells = <0x02>;
				#address-cells = <0x02>;
				interrupts = <0x64>;
				gpmc,num-cs = <0x07>;
				#size-cells = <0x01>;
				dma-names = "rxtx";
				phandle = <0xf0>;
				reg = <0x50000000 0x2000>;
				#gpio-cells = <0x02>;
				dmas = <0x24 0x34 0x00>;
				interrupt-controller;
			};
		};

		target-module@47400000 {
			ti,sysc-midle = <0x00 0x01 0x02>;
			compatible = "ti,sysc-omap4\0ti,sysc";
			clocks = <0x35 0x00 0x00>;
			reg-names = "rev\0sysc";
			clock-names = "fck";
			ti,sysc-delay-us = <0x02>;
			ti,sysc-mask = <0x03>;
			ranges = <0x00 0x47400000 0x8000>;
			#address-cells = <0x01>;
			#size-cells = <0x01>;
			ti,sysc-sidle = <0x00 0x01 0x02 0x03>;
			phandle = <0xeb>;
			reg = <0x47400000 0x04 0x47400010 0x04>;

			usb-phy@1300 {
				compatible = "ti,am335x-usb-phy";
				reg-names = "phy";
				phandle = <0x58>;
				reg = <0x1300 0x100>;
				#phy-cells = <0x00>;
				ti,ctrl_mod = <0x57>;
			};

			usb@1800 {
				mentor,num-eps = <0x10>;
				mentor,power = <0x1f4>;
				compatible = "ti,musb-am33xx";
				reg-names = "mc\0control";
				mentor,multipoint = <0x01>;
				interrupts = <0x13>;
				dma-names = "rx1\0rx2\0rx3\0rx4\0rx5\0rx6\0rx7\0rx8\0rx9\0rx10\0rx11\0rx12\0rx13\0rx14\0rx15\0tx1\0tx2\0tx3\0tx4\0tx5\0tx6\0tx7\0tx8\0tx9\0tx10\0tx11\0tx12\0tx13\0tx14\0tx15";
				phandle = <0xed>;
				mentor,ram-bits = <0x0c>;
				phys = <0x5b>;
				reg = <0x1c00 0x400 0x1800 0x200>;
				dmas = <0x59 0x0f 0x00 0x59 0x10 0x00 0x59 0x11 0x00 0x59 0x12 0x00 0x59 0x13 0x00 0x59 0x14 0x00 0x59 0x15 0x00 0x59 0x16 0x00 0x59 0x17 0x00 0x59 0x18 0x00 0x59 0x19 0x00 0x59 0x1a 0x00 0x59 0x1b 0x00 0x59 0x1c 0x00 0x59 0x1d 0x00 0x59 0x0f 0x01 0x59 0x10 0x01 0x59 0x11 0x01 0x59 0x12 0x01 0x59 0x13 0x01 0x59 0x14 0x01 0x59 0x15 0x01 0x59 0x16 0x01 0x59 0x17 0x01 0x59 0x18 0x01 0x59 0x19 0x01 0x59 0x1a 0x01 0x59 0x1b 0x01 0x59 0x1c 0x01 0x59 0x1d 0x01>;
				dr_mode = "host";
				interrupt-names = "mc";
			};

			usb-phy@1b00 {
				compatible = "ti,am335x-usb-phy";
				reg-names = "phy";
				phandle = <0x5b>;
				reg = <0x1b00 0x100>;
				#phy-cells = <0x00>;
				ti,ctrl_mod = <0x57>;
			};

			usb@1400 {
				mentor,num-eps = <0x10>;
				mentor,power = <0x1f4>;
				interrupts-extended = <0x01 0x12 0x5a 0x00>;
				compatible = "ti,musb-am33xx";
				reg-names = "mc\0control";
				mentor,multipoint = <0x01>;
				interrupts = <0x12>;
				dma-names = "rx1\0rx2\0rx3\0rx4\0rx5\0rx6\0rx7\0rx8\0rx9\0rx10\0rx11\0rx12\0rx13\0rx14\0rx15\0tx1\0tx2\0tx3\0tx4\0tx5\0tx6\0tx7\0tx8\0tx9\0tx10\0tx11\0tx12\0tx13\0tx14\0tx15";
				phandle = <0xec>;
				mentor,ram-bits = <0x0c>;
				phys = <0x58>;
				reg = <0x1400 0x400 0x1000 0x200>;
				dmas = <0x59 0x00 0x00 0x59 0x01 0x00 0x59 0x02 0x00 0x59 0x03 0x00 0x59 0x04 0x00 0x59 0x05 0x00 0x59 0x06 0x00 0x59 0x07 0x00 0x59 0x08 0x00 0x59 0x09 0x00 0x59 0x0a 0x00 0x59 0x0b 0x00 0x59 0x0c 0x00 0x59 0x0d 0x00 0x59 0x0e 0x00 0x59 0x00 0x01 0x59 0x01 0x01 0x59 0x02 0x01 0x59 0x03 0x01 0x59 0x04 0x01 0x59 0x05 0x01 0x59 0x06 0x01 0x59 0x07 0x01 0x59 0x08 0x01 0x59 0x09 0x01 0x59 0x0a 0x01 0x59 0x0b 0x01 0x59 0x0c 0x01 0x59 0x0d 0x01 0x59 0x0e 0x01>;
				dr_mode = "peripheral";
				interrupt-names = "mc\0vbus";
			};

			dma-controller@2000 {
				#dma-cells = <0x02>;
				compatible = "ti,am3359-cppi41";
				dma-requests = <0x100>;
				reg-names = "glue\0controller\0scheduler\0queuemgr";
				dma-channels = <0x1e>;
				#dma-requests = <0x100>;
				interrupts = <0x11>;
				phandle = <0x59>;
				reg = <0x00 0x1000 0x2000 0x1000 0x3000 0x1000 0x4000 0x4000>;
				#dma-channels = <0x1e>;
				interrupt-names = "glue";
			};
		};

		target-module@56000000 {
			ti,sysc-midle = <0x00 0x01 0x02>;
			power-domains = <0x5d>;
			compatible = "ti,sysc-omap4\0ti,sysc";
			clocks = <0x5c 0x04 0x00>;
			resets = <0x5d 0x00>;
			reg-names = "rev\0sysc";
			clock-names = "fck";
			ranges = <0x00 0x56000000 0x1000000>;
			#address-cells = <0x01>;
			#size-cells = <0x01>;
			ti,sysc-sidle = <0x00 0x01 0x02>;
			reg = <0x5600fe00 0x04 0x5600fe10 0x04>;
			reset-names = "rstctrl";

			gpu@0 {
				compatible = "ti,omap3630-gpu\0img,powervr-sgx530";
				interrupts = <0x25>;
				reg = <0x00 0x10000>;
			};
		};

		target-module@49800000 {
			ti,sysc-midle = <0x00>;
			compatible = "ti,sysc-omap4\0ti,sysc";
			clocks = <0x07 0x00 0x00>;
			reg-names = "rev\0sysc";
			clock-names = "fck";
			ti,sysc-mask = <0x01>;
			ranges = <0x00 0x49800000 0x100000>;
			#address-cells = <0x01>;
			#size-cells = <0x01>;
			ti,sysc-sidle = <0x00 0x02>;
			reg = <0x49800000 0x04 0x49800010 0x04>;

			dma@0 {
				compatible = "ti,edma3-tptc";
				interrupts = <0x70>;
				phandle = <0x54>;
				reg = <0x00 0x100000>;
				interrupt-names = "edma3_tcerrint";
			};
		};
	};

	leds {
		compatible = "gpio-leds";
		pinctrl-0 = <0x5e>;
		pinctrl-names = "default";

		led4 {
			gpios = <0x51 0x17 0x00>;
			label = "beaglebone:green:usr2";
			default-state = "off";
			linux,default-trigger = "cpu0";
		};

		led2 {
			gpios = <0x51 0x15 0x00>;
			label = "beaglebone:green:usr0";
			default-state = "off";
			linux,default-trigger = "heartbeat";
		};

		led5 {
			gpios = <0x51 0x18 0x00>;
			label = "beaglebone:green:usr3";
			default-state = "off";
			linux,default-trigger = "mmc1";
		};

		led3 {
			gpios = <0x51 0x16 0x00>;
			label = "beaglebone:green:usr1";
			default-state = "off";
			linux,default-trigger = "mmc0";
		};
	};

	aliases {
		i2c1 = "/ocp/interconnect@48000000/segment@0/target-module@2a000/i2c@0";
		spi0 = "/ocp/interconnect@48000000/segment@0/target-module@30000/spi@0";
		mmc1 = "/ocp/interconnect@48000000/segment@100000/target-module@d8000/mmc@0";
		usb1 = "/ocp/target-module@47400000/usb@1800";
		d-can0 = "/ocp/interconnect@48000000/segment@100000/target-module@cc000/can@0";
		serial5 = "/ocp/interconnect@48000000/segment@100000/target-module@aa000/serial@0";
		phy1 = "/ocp/target-module@47400000/usb-phy@1b00";
		ethernet0 = "/ocp/interconnect@4a000000/segment@0/target-module@100000/switch@0/ethernet-ports/port@1";
		serial3 = "/ocp/interconnect@48000000/segment@100000/target-module@a6000/serial@0";
		serial1 = "/ocp/interconnect@48000000/segment@0/target-module@22000/serial@0";
		i2c2 = "/ocp/interconnect@48000000/segment@100000/target-module@9c000/i2c@0";
		spi1 = "/ocp/interconnect@48000000/segment@100000/target-module@a0000/spi@0";
		i2c0 = "/ocp/interconnect@44c00000/segment@200000/target-module@b000/i2c@0";
		mmc2 = "/ocp/target-module@47810000/mmc@0";
		d-can1 = "/ocp/interconnect@48000000/segment@100000/target-module@d0000/can@0";
		ethernet1 = "/ocp/interconnect@4a000000/segment@0/target-module@100000/switch@0/ethernet-ports/port@2";
		mmc0 = "/ocp/interconnect@48000000/segment@0/target-module@60000/mmc@0";
		usb0 = "/ocp/target-module@47400000/usb@1400";
		serial4 = "/ocp/interconnect@48000000/segment@100000/target-module@a8000/serial@0";
		phy0 = "/ocp/target-module@47400000/usb-phy@1300";
		serial2 = "/ocp/interconnect@48000000/segment@0/target-module@24000/serial@0";
		serial0 = "/ocp/interconnect@44c00000/segment@200000/target-module@9000/serial@0";
	};

	chosen {
		stdout-path = "serial0:115200n8";
		bootargs = "console=ttyS0,115200n8 root=/dev/mmcblk0p3 ro rootfstype=ext4 rootwait fsck.repair=yes earlycon coherent_pool=1M net.ifnames=0 lpj=1990656 rng_core.default_quality=100";
		linux,initrd-start = <0x8f776000>;
		base_dtb = "am335x-boneblack-uboot.dts";
		linux,initrd-end = <0x8ffff1bb>;
		base_dtb_timestamp = "Fri Aug 28 00:33:52 2026";
	};

	memory@80000000 {
		device_type = "memory";
		reg = <0x80000000 0x20000000>;
	};

	fixedregulator0 {
		compatible = "regulator-fixed";
		phandle = <0x39>;
		regulator-min-microvolt = <0x325aa0>;
		regulator-max-microvolt = <0x325aa0>;
		regulator-name = "vmmcsd_fixed";
	};

	cpus {
		#address-cells = <0x01>;
		#size-cells = <0x00>;

		idle-states {

			mpu_gate {
				compatible = "arm,idle-state";
				ti,idle-wkup-m3;
				phandle = <0x04>;
				exit-latency-us = <0x5a>;
				entry-latency-us = <0x28>;
				min-residency-us = <0x12c>;
			};
		};

		cpu@0 {
			compatible = "arm,cortex-a8";
			clocks = <0x03>;
			cpu-idle-states = <0x04>;
			device_type = "cpu";
			cpu0-supply = <0x05>;
			clock-names = "cpu";
			enable-method = "ti,am3352";
			phandle = <0x5f>;
			operating-points-v2 = <0x02>;
			reg = <0x00>;
			clock-latency = <0x493e0>;
		};
	};

	not_available {
		phandle = <0xf5>;
	};
};
